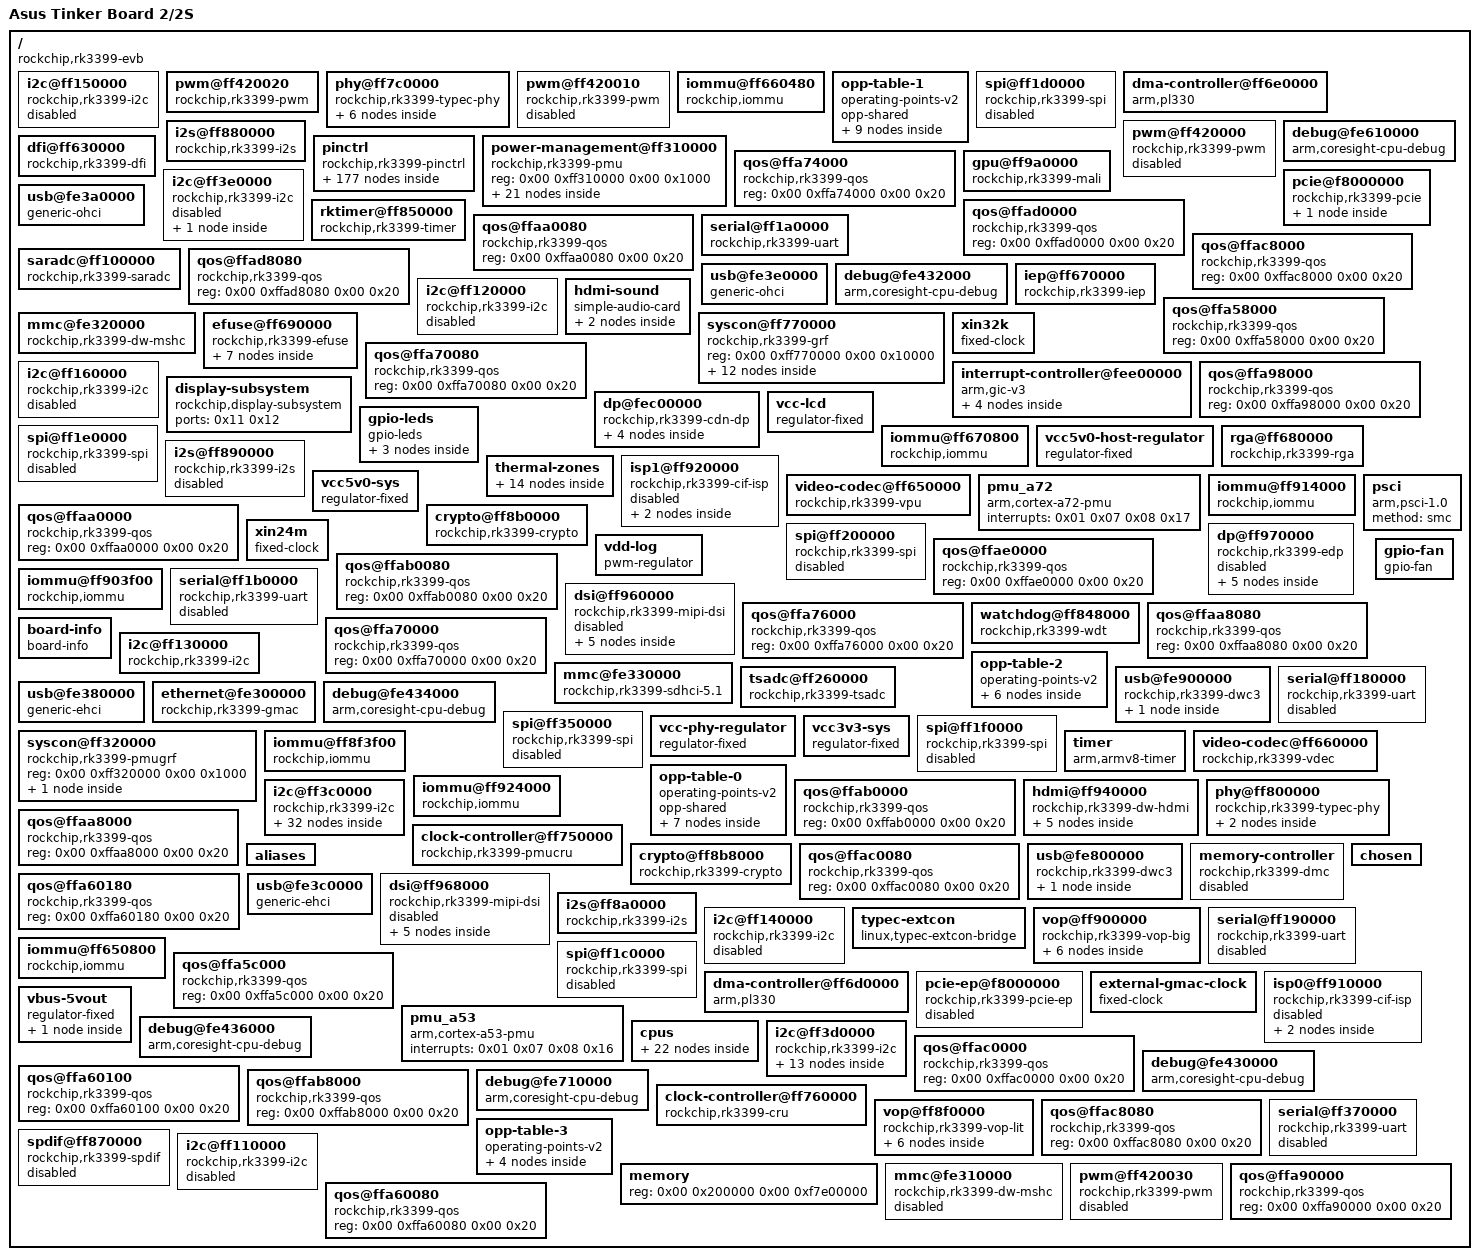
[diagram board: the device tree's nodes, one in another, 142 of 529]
/dts-v1/;

/ {
	#address-cells = <0x02>;
	model = "Asus Tinker Board 2/2S";
	serial-number = "3ae0242313a34723";
	#size-cells = <0x02>;
	interrupt-parent = <0x01>;
	compatible = "rockchip,rk3399-evb", "rockchip,rk3399";

	i2c@ff150000 {
		pinctrl-names = "default";
		#address-cells = <0x01>;
		pinctrl-0 = <0x3a>;
		clock-names = "i2c", "pclk";
		assigned-clocks = <0x08 0x45>;
		assigned-clock-rates = <0xbebc200>;
		interrupts = <0x00 0x25 0x04 0x00>;
		clocks = <0x08 0x45 0x08 0x159>;
		#size-cells = <0x00>;
		compatible = "rockchip,rk3399-i2c";
		status = "disabled";
		reg = <0x00 0xff150000 0x00 0x1000>;
		phandle = <0xd8>;
	};

	pwm@ff420020 {
		pinctrl-names = "default";
		pinctrl-0 = <0x89>;
		clocks = <0x72 0x1e>;
		#pwm-cells = <0x03>;
		compatible = "rockchip,rk3399-pwm", "rockchip,rk3288-pwm";
		status = "okay";
		reg = <0x00 0xff420020 0x00 0x10>;
		phandle = <0xc1>;
	};

	phy@ff7c0000 {
		power-domains = <0x1e 0x08>;
		clock-names = "tcpdcore", "tcpdphy-ref";
		assigned-clocks = <0x08 0x7e>;
		assigned-clock-rates = <0x2faf080>;
		resets = <0x08 0x95 0x08 0x94 0x08 0x14c>;
		clocks = <0x08 0x7e 0x08 0x7d>;
		extcon = <0x30>;
		compatible = "rockchip,rk3399-typec-phy";
		status = "okay";
		rockchip,grf = <0x1f>;
		reg = <0x00 0xff7c0000 0x00 0x40000>;
		phandle = <0x110>;
		reset-names = "uphy", "uphy-pipe", "uphy-tcphy";

		dp-port {
			#phy-cells = <0x00>;
			phandle = <0x33>;

			port {

				endpoint {
					remote-endpoint = <0x92>;
					phandle = <0x84>;
				};
			};
		};

		usb3-port {
			#phy-cells = <0x00>;
			phandle = <0x2f>;

			port {

				endpoint {
					remote-endpoint = <0x93>;
					phandle = <0x83>;
				};
			};
		};
	};

	pwm@ff420010 {
		pinctrl-names = "default";
		pinctrl-0 = <0x88>;
		clocks = <0x72 0x1e>;
		#pwm-cells = <0x03>;
		compatible = "rockchip,rk3399-pwm", "rockchip,rk3288-pwm";
		status = "disabled";
		reg = <0x00 0xff420010 0x00 0x10>;
		phandle = <0x101>;
	};

	iommu@ff660480 {
		power-domains = <0x1e 0x20>;
		clock-names = "aclk", "iface";
		interrupts = <0x00 0x75 0x04 0x00>;
		clocks = <0x08 0xed 0x08 0x1ec>;
		#iommu-cells = <0x00>;
		compatible = "rockchip,iommu";
		reg = <0x00 0xff660480 0x00 0x40 0x00 0xff6604c0 0x00 0x40>;
		phandle = <0x8c>;
	};

	opp-table-1 {
		opp-shared;
		compatible = "operating-points-v2";
		phandle = <0x0f>;

		opp04 {
			opp-microvolt = <0xdbba0 0xdbba0 0x1312d0>;
			opp-hz = <0x00 0x47868c00>;
		};

		opp02 {
			opp-microvolt = <0xc96a8 0xc96a8 0x1312d0>;
			opp-hz = <0x00 0x30a32c00>;
		};

		opp00 {
			opp-microvolt = <0xc3500 0xc3500 0x1312d0>;
			opp-hz = <0x00 0x18519600>;
			clock-latency-ns = <0x9c40>;
		};

		opp07 {
			opp-microvolt = <0x118c30 0x118c30 0x1312d0>;
			opp-hz = <0x00 0x6b49d200>;
		};

		opp05 {
			opp-microvolt = <0xee098 0xee098 0x1312d0>;
			opp-hz = <0x00 0x54667200>;
		};

		opp03 {
			opp-microvolt = <0xcf850 0xcf850 0x1312d0>;
			opp-hz = <0x00 0x3c14dc00>;
		};

		opp01 {
			opp-microvolt = <0xc3500 0xc3500 0x1312d0>;
			opp-hz = <0x00 0x23c34600>;
		};

		opp08 {
			opp-microvolt = <0x1312d0 0x1312d0 0x1312d0>;
			opp-hz = <0x00 0x7829b800>;
		};

		opp06 {
			opp-microvolt = <0x100590 0x100590 0x1312d0>;
			opp-hz = <0x00 0x5fd82200>;
		};
	};

	spi@ff1d0000 {
		pinctrl-names = "default";
		#address-cells = <0x01>;
		pinctrl-0 = <0x45 0x46 0x47 0x48>;
		clock-names = "spiclk", "apb_pclk";
		interrupts = <0x00 0x35 0x04 0x00>;
		clocks = <0x08 0x48 0x08 0x15c>;
		#size-cells = <0x00>;
		dma-names = "tx", "rx";
		compatible = "rockchip,rk3399-spi", "rockchip,rk3066-spi";
		status = "disabled";
		reg = <0x00 0xff1d0000 0x00 0x1000>;
		phandle = <0xdf>;
		dmas = <0x40 0x0c 0x40 0x0d>;
	};

	dma-controller@ff6e0000 {
		clock-names = "apb_pclk";
		interrupts = <0x00 0x07 0x04 0x00 0x00 0x08 0x04 0x00>;
		clocks = <0x08 0xd4>;
		arm,pl330-periph-burst;
		compatible = "arm,pl330", "arm,primecell";
		reg = <0x00 0xff6e0000 0x00 0x4000>;
		phandle = <0x40>;
		#dma-cells = <0x01>;
	};

	i2s@ff880000 {
		power-domains = <0x1e 0x1c>;
		rockchip,capture-channels = <0x08>;
		pinctrl-names = "bclk_on", "bclk_off";
		pinctrl-0 = <0x95>;
		clock-names = "i2s_clk", "i2s_hclk";
		interrupts = <0x00 0x27 0x04 0x00>;
		clocks = <0x08 0x56 0x08 0x1d4>;
		dma-names = "tx", "rx";
		#sound-dai-cells = <0x00>;
		rockchip,playback-channels = <0x08>;
		compatible = "rockchip,rk3399-i2s", "rockchip,rk3066-i2s";
		pinctrl-1 = <0x96>;
		status = "okay";
		rockchip,grf = <0x1f>;
		reg = <0x00 0xff880000 0x00 0x1000>;
		phandle = <0x115>;
		dmas = <0x51 0x00 0x51 0x01>;
	};

	pwm@ff420000 {
		pinctrl-names = "default";
		pinctrl-0 = <0x87>;
		clocks = <0x72 0x1e>;
		#pwm-cells = <0x03>;
		compatible = "rockchip,rk3399-pwm", "rockchip,rk3288-pwm";
		status = "disabled";
		reg = <0x00 0xff420000 0x00 0x10>;
		phandle = <0x100>;
	};

	debug@fe610000 {
		clock-names = "apb_pclk";
		clocks = <0x08 0x14c>;
		cpu = <0x06>;
		compatible = "arm,coresight-cpu-debug", "arm,primecell";
		reg = <0x00 0xfe610000 0x00 0x1000>;
	};

	pinctrl {
		#address-cells = <0x02>;
		#size-cells = <0x02>;
		compatible = "rockchip,rk3399-pinctrl";
		rockchip,pmu = <0x13>;
		ranges;
		rockchip,grf = <0x1f>;
		phandle = <0x126>;

		i2c3 {

			i2c3-xfer {
				rockchip,pins = <0x04 0x11 0x01 0xb6 0x04 0x10 0x01 0xb6>;
				phandle = <0x38>;
			};
		};

		clock {

			clk-32k {
				rockchip,pins = <0x00 0x00 0x02 0xb6>;
				phandle = <0x136>;
			};
		};

		spi2 {

			spi2-clk {
				rockchip,pins = <0x02 0x0b 0x01 0xb9>;
				phandle = <0x49>;
			};

			spi2-cs0 {
				rockchip,pins = <0x02 0x0c 0x01 0xb9>;
				phandle = <0x4c>;
			};

			spi2-tx {
				rockchip,pins = <0x02 0x0a 0x01 0xb9>;
				phandle = <0x4a>;
			};

			spi2-rx {
				rockchip,pins = <0x02 0x09 0x01 0xb9>;
				phandle = <0x4b>;
			};
		};

		pcfg-pull-none-12ma {
			drive-strength = <0x0c>;
			bias-disable;
			phandle = <0xb8>;
		};

		pcfg-pull-up-20ma {
			drive-strength = <0x14>;
			phandle = <0x12b>;
			bias-pull-up;
		};

		gpio@ff720000 {
			gpio-controller;
			interrupts = <0x00 0x0e 0x04 0x00>;
			clocks = <0x72 0x17>;
			compatible = "rockchip,gpio-bank";
			#interrupt-cells = <0x02>;
			reg = <0x00 0xff720000 0x00 0x100>;
			phandle = <0x1b>;
			#gpio-cells = <0x02>;
			interrupt-controller;
		};

		pcfg-input-pull-up {
			phandle = <0x134>;
			bias-pull-up;
			input-enable;
		};

		i2s1 {

			i2s1-2ch-bus-bclk-off {
				rockchip,pins = <0x04 0x03 0x00 0xb6 0x04 0x04 0x01 0xb6 0x04 0x05 0x01 0xb6 0x04 0x06 0x01 0xb6 0x04 0x07 0x01 0xb6>;
				phandle = <0x13c>;
			};

			i2s1-2ch-bus {
				rockchip,pins = <0x04 0x03 0x01 0xb6 0x04 0x04 0x01 0xb6 0x04 0x05 0x01 0xb6 0x04 0x06 0x01 0xb6 0x04 0x07 0x01 0xb6>;
				phandle = <0x97>;
			};
		};

		i2c1 {

			i2c1-xfer {
				rockchip,pins = <0x04 0x02 0x01 0xb6 0x04 0x01 0x01 0xb6>;
				phandle = <0x36>;
			};
		};

		gmac {

			rmii-pins {
				rockchip,pins = <0x03 0x0d 0x01 0xb6 0x03 0x0c 0x01 0xb7 0x03 0x0b 0x01 0xb6 0x03 0x0a 0x01 0xb6 0x03 0x09 0x01 0xb6 0x03 0x08 0x01 0xb6 0x03 0x07 0x01 0xb6 0x03 0x06 0x01 0xb6 0x03 0x05 0x01 0xb7 0x03 0x04 0x01 0xb7>;
				phandle = <0x139>;
			};

			rgmii-pins {
				rockchip,pins = <0x03 0x11 0x01 0xb7 0x03 0x0e 0x01 0xb6 0x03 0x0d 0x01 0xb6 0x03 0x0c 0x01 0xb7 0x03 0x0b 0x01 0xb6 0x03 0x09 0x01 0xb6 0x03 0x08 0x01 0xb6 0x03 0x07 0x01 0xb6 0x03 0x06 0x01 0xb6 0x03 0x05 0x01 0xb7 0x03 0x04 0x01 0xb7 0x03 0x03 0x01 0xb6 0x03 0x02 0x01 0xb6 0x03 0x01 0x01 0xb7 0x03 0x00 0x01 0xb7>;
				phandle = <0x21>;
			};
		};

		usb-typec {

			vcc5v0-typec0-en-pin {
				rockchip,pins = <0x01 0x03 0x00 0xb9>;
				phandle = <0xc0>;
			};
		};

		spi0 {

			spi0-tx {
				rockchip,pins = <0x03 0x05 0x02 0xb9>;
				phandle = <0x42>;
			};

			spi0-rx {
				rockchip,pins = <0x03 0x04 0x02 0xb9>;
				phandle = <0x43>;
			};

			spi0-cs1 {
				rockchip,pins = <0x03 0x08 0x02 0xb9>;
				phandle = <0x14c>;
			};

			spi0-clk {
				rockchip,pins = <0x03 0x06 0x02 0xb9>;
				phandle = <0x41>;
			};

			spi0-cs0 {
				rockchip,pins = <0x03 0x07 0x02 0xb9>;
				phandle = <0x44>;
			};
		};

		pcfg-pull-down-4ma {
			drive-strength = <0x04>;
			bias-pull-down;
			phandle = <0x12c>;
		};

		pcfg-pull-down {
			bias-pull-down;
			phandle = <0xbb>;
		};

		uart4 {

			uart4-xfer {
				rockchip,pins = <0x01 0x07 0x01 0xb9 0x01 0x08 0x01 0xb6>;
				phandle = <0x77>;
			};
		};

		pcfg-pull-none-18ma {
			drive-strength = <0x12>;
			bias-disable;
			phandle = <0x127>;
		};

		i2c8 {

			i2c8-xfer {
				rockchip,pins = <0x01 0x15 0x01 0xb6 0x01 0x14 0x01 0xb6>;
				phandle = <0x86>;
			};
		};

		pcfg-input-pull-down {
			bias-pull-down;
			phandle = <0x135>;
			input-enable;
		};

		pcfg-pull-none-20ma {
			drive-strength = <0x14>;
			bias-disable;
			phandle = <0x128>;
		};

		gpio@ff730000 {
			gpio-controller;
			interrupts = <0x00 0x0f 0x04 0x00>;
			clocks = <0x72 0x18>;
			compatible = "rockchip,gpio-bank";
			#interrupt-cells = <0x02>;
			reg = <0x00 0xff730000 0x00 0x100>;
			phandle = <0x79>;
			#gpio-cells = <0x02>;
			interrupt-controller;
		};

		i2c6 {

			i2c6-xfer {
				rockchip,pins = <0x02 0x0a 0x02 0xb6 0x02 0x09 0x02 0xb6>;
				phandle = <0x3a>;
			};
		};

		uarthdcp {

			uarthdcp-xfer {
				rockchip,pins = <0x04 0x15 0x02 0xb9 0x04 0x16 0x02 0xb6>;
				phandle = <0x156>;
			};
		};

		pwm1 {

			pwm1-pin {
				rockchip,pins = <0x04 0x16 0x01 0xb6>;
				phandle = <0x88>;
			};

			pwm1-pin-pull-down {
				rockchip,pins = <0x04 0x16 0x01 0xbb>;
				phandle = <0x15a>;
			};
		};

		uart2b {

			uart2b-xfer {
				rockchip,pins = <0x04 0x10 0x02 0xb9 0x04 0x11 0x02 0xb6>;
				phandle = <0x153>;
			};
		};

		edp {

			edp-hpd {
				rockchip,pins = <0x04 0x17 0x02 0xb6>;
				phandle = <0xb1>;
			};
		};

		spi5 {

			spi5-cs0 {
				rockchip,pins = <0x02 0x17 0x02 0xb9>;
				phandle = <0x55>;
			};

			spi5-tx {
				rockchip,pins = <0x02 0x15 0x02 0xb9>;
				phandle = <0x53>;
			};

			spi5-rx {
				rockchip,pins = <0x02 0x14 0x02 0xb9>;
				phandle = <0x54>;
			};

			spi5-clk {
				rockchip,pins = <0x02 0x16 0x02 0xb9>;
				phandle = <0x52>;
			};
		};

		tsadc {

			otp-pin {
				rockchip,pins = <0x01 0x06 0x00 0xb6>;
				phandle = <0x5b>;
			};

			otp-out {
				rockchip,pins = <0x01 0x06 0x01 0xb6>;
				phandle = <0x5c>;
			};
		};

		uart0 {

			uart0-cts {
				rockchip,pins = <0x02 0x12 0x01 0xb6>;
				phandle = <0x150>;
			};

			uart0-rts {
				rockchip,pins = <0x02 0x13 0x01 0xb6>;
				phandle = <0x151>;
			};

			uart0-xfer {
				rockchip,pins = <0x02 0x10 0x01 0xb9 0x02 0x11 0x01 0xb6>;
				phandle = <0x3c>;
			};
		};

		i2c4 {

			i2c4-xfer {
				rockchip,pins = <0x01 0x0c 0x01 0xb6 0x01 0x0b 0x01 0xb6>;
				phandle = <0x7f>;
			};
		};

		pcfg-pull-down-12ma {
			drive-strength = <0x0c>;
			bias-pull-down;
			phandle = <0x12e>;
		};

		spdif {

			spdif-bus-1 {
				rockchip,pins = <0x03 0x10 0x03 0xb6>;
				phandle = <0x14b>;
			};

			spdif-bus {
				rockchip,pins = <0x04 0x15 0x01 0xb6>;
				phandle = <0x94>;
			};
		};

		pcfg-output-high {
			output-high;
			phandle = <0x131>;
		};

		pcie {

			pci-clkreqn-cpm {
				rockchip,pins = <0x02 0x1a 0x00 0xb6>;
				phandle = <0x1c>;
			};

			pci-clkreqnb-cpm {
				rockchip,pins = <0x04 0x18 0x00 0xb6>;
				phandle = <0x1d>;
			};
		};

		pcfg-pull-up {
			phandle = <0xb9>;
			bias-pull-up;
		};

		spi3 {

			spi3-tx {
				rockchip,pins = <0x01 0x10 0x01 0xb9>;
				phandle = <0x74>;
			};

			spi3-rx {
				rockchip,pins = <0x01 0x0f 0x01 0xb9>;
				phandle = <0x75>;
			};

			spi3-clk {
				rockchip,pins = <0x01 0x11 0x01 0xb9>;
				phandle = <0x73>;
			};

			spi3-cs0 {
				rockchip,pins = <0x01 0x12 0x01 0xb9>;
				phandle = <0x76>;
			};
		};

		pwm3a {

			pwm3a-pin {
				rockchip,pins = <0x00 0x06 0x01 0xb6>;
				phandle = <0x8a>;
			};
		};

		sdio0 {

			sdio0-clk {
				rockchip,pins = <0x02 0x19 0x01 0xb6>;
				phandle = <0x140>;
			};

			sdio0-wp {
				rockchip,pins = <0x00 0x03 0x01 0xb9>;
				phandle = <0x144>;
			};

			sdio0-bus4 {
				rockchip,pins = <0x02 0x14 0x01 0xb9 0x02 0x15 0x01 0xb9 0x02 0x16 0x01 0xb9 0x02 0x17 0x01 0xb9>;
				phandle = <0x13e>;
			};

			sdmmc-pwr {
				rockchip,pins = <0x00 0x01 0x01 0xb9>;
				phandle = <0x146>;
			};

			sdio0-bkpwr {
				rockchip,pins = <0x02 0x1c 0x01 0xb9>;
				phandle = <0x143>;
			};

			sdio0-cd {
				rockchip,pins = <0x02 0x1a 0x01 0xb9>;
				phandle = <0x141>;
			};

			sdio0-pwr {
				rockchip,pins = <0x02 0x1b 0x01 0xb9>;
				phandle = <0x142>;
			};

			sdio0-int {
				rockchip,pins = <0x00 0x04 0x01 0xb9>;
				phandle = <0x145>;
			};

			sdio0-bus1 {
				rockchip,pins = <0x02 0x14 0x01 0xb9>;
				phandle = <0x13d>;
			};

			sdio0-cmd {
				rockchip,pins = <0x02 0x18 0x01 0xb9>;
				phandle = <0x13f>;
			};
		};

		pcfg-pull-up-2ma {
			drive-strength = <0x02>;
			phandle = <0x129>;
			bias-pull-up;
		};

		i2c2 {

			i2c2-xfer {
				rockchip,pins = <0x02 0x01 0x02 0xb8 0x02 0x00 0x02 0xb8>;
				phandle = <0x37>;
			};
		};

		pmic {

			vsel2-gpio {
				rockchip,pins = <0x01 0x0e 0x00 0xbb>;
				phandle = <0x85>;
			};

			vsel1-gpio {
				rockchip,pins = <0x01 0x11 0x00 0xbb>;
				phandle = <0x7e>;
			};

			pmic-int-l {
				rockchip,pins = <0x01 0x12 0x00 0xb9 0x00 0x09 0x00 0xb6>;
				phandle = <0x7a>;
			};
		};

		pcfg-input-enable {
			phandle = <0x133>;
			input-enable;
		};

		pcfg-pull-none {
			bias-disable;
			phandle = <0xb6>;
		};

		spi1 {

			spi1-cs0 {
				rockchip,pins = <0x01 0x0a 0x02 0xb9>;
				phandle = <0x48>;
			};

			spi1-clk {
				rockchip,pins = <0x01 0x09 0x02 0xb9>;
				phandle = <0x45>;
			};

			spi1-tx {
				rockchip,pins = <0x01 0x08 0x02 0xb9>;
				phandle = <0x46>;
			};

			spi1-rx {
				rockchip,pins = <0x01 0x07 0x02 0xb9>;
				phandle = <0x47>;
			};
		};

		gpio@ff780000 {
			gpio-controller;
			interrupts = <0x00 0x10 0x04 0x00>;
			clocks = <0x08 0x150>;
			compatible = "rockchip,gpio-bank";
			#interrupt-cells = <0x02>;
			reg = <0x00 0xff780000 0x00 0x100>;
			phandle = <0xbd>;
			#gpio-cells = <0x02>;
			interrupt-controller;
		};

		pcfg-pull-down-18ma {
			drive-strength = <0x12>;
			bias-pull-down;
			phandle = <0x12f>;
		};

		sdmmc {

			sdmmc-wp {
				rockchip,pins = <0x00 0x08 0x01 0xba>;
				phandle = <0x148>;
			};

			sdmmc-bus1 {
				rockchip,pins = <0x04 0x08 0x01 0xba>;
				phandle = <0x147>;
			};

			sdmmc-cd {
				rockchip,pins = <0x00 0x07 0x01 0xb9>;
				phandle = <0x27>;
			};

			sdmmc-bus4 {
				rockchip,pins = <0x04 0x08 0x01 0xba 0x04 0x09 0x01 0xba 0x04 0x0a 0x01 0xba 0x04 0x0b 0x01 0xba>;
				phandle = <0x28>;
			};

			sdmmc-cmd {
				rockchip,pins = <0x04 0x0d 0x01 0xba>;
				phandle = <0x26>;
			};

			sdmmc-clk {
				rockchip,pins = <0x04 0x0c 0x01 0xb8>;
				phandle = <0x25>;
			};
		};

		i2s0 {

			i2s0-8ch-bus {
				rockchip,pins = <0x03 0x18 0x01 0xb6 0x03 0x19 0x01 0xb6 0x03 0x1a 0x01 0xb6 0x03 0x1b 0x01 0xb6 0x03 0x1c 0x01 0xb6 0x03 0x1d 0x01 0xb6 0x03 0x1e 0x01 0xb6 0x03 0x1f 0x01 0xb6 0x04 0x00 0x01 0xb6>;
				phandle = <0x95>;
			};

			i2s0-8ch-bus-bclk-off {
				rockchip,pins = <0x03 0x18 0x00 0xb6 0x03 0x19 0x01 0xb6 0x03 0x1a 0x01 0xb6 0x03 0x1b 0x01 0xb6 0x03 0x1c 0x01 0xb6 0x03 0x1d 0x01 0xb6 0x03 0x1e 0x01 0xb6 0x03 0x1f 0x01 0xb6 0x04 0x00 0x01 0xb6>;
				phandle = <0x96>;
			};

			i2s0-2ch-bus-bclk-off {
				rockchip,pins = <0x03 0x18 0x00 0xb6 0x03 0x19 0x01 0xb6 0x03 0x1a 0x01 0xb6 0x03 0x1b 0x01 0xb6 0x03 0x1f 0x01 0xb6 0x04 0x00 0x01 0xb6>;
				phandle = <0x13b>;
			};

			i2s0-2ch-bus {
				rockchip,pins = <0x03 0x18 0x01 0xb6 0x03 0x19 0x01 0xb6 0x03 0x1a 0x01 0xb6 0x03 0x1b 0x01 0xb6 0x03 0x1f 0x01 0xb6 0x04 0x00 0x01 0xb6>;
				phandle = <0x13a>;
			};
		};

		i2c0 {

			i2c0-xfer {
				rockchip,pins = <0x01 0x0f 0x02 0xb6 0x01 0x10 0x02 0xb6>;
				phandle = <0x78>;
			};
		};

		suspend {

			ap-pwroff {
				rockchip,pins = <0x01 0x05 0x01 0xb6>;
				phandle = <0x149>;
			};

			ddrio-pwroff {
				rockchip,pins = <0x00 0x01 0x01 0xb6>;
				phandle = <0x14a>;
			};
		};

		usb2 {

			vcc5v0-host-en {
				rockchip,pins = <0x04 0x19 0x00 0xb6>;
				phandle = <0xbf>;
			};
		};

		testclk {

			test-clkout2 {
				rockchip,pins = <0x00 0x08 0x03 0xb6>;
				phandle = <0x14f>;
			};

			test-clkout0 {
				rockchip,pins = <0x00 0x00 0x01 0xb6>;
				phandle = <0x14d>;
			};

			test-clkout1 {
				rockchip,pins = <0x02 0x19 0x02 0xb6>;
				phandle = <0x14e>;
			};
		};

		pcfg-pull-up-8ma {
			drive-strength = <0x08>;
			phandle = <0xba>;
			bias-pull-up;
		};

		pcfg-pull-down-20ma {
			drive-strength = <0x14>;
			bias-pull-down;
			phandle = <0x130>;
		};

		pcfg-pull-none-13ma {
			drive-strength = <0x0d>;
			bias-disable;
			phandle = <0xb7>;
		};

		fusb30x {

			fusb0-int {
				rockchip,pins = <0x01 0x02 0x00 0xb9>;
				phandle = <0x80>;
			};
		};

		uart3 {

			uart3-cts {
				rockchip,pins = <0x03 0x10 0x02 0xb6>;
				phandle = <0x154>;
			};

			uart3-rts {
				rockchip,pins = <0x03 0x11 0x02 0xb6>;
				phandle = <0x155>;
			};

			uart3-xfer {
				rockchip,pins = <0x03 0x0e 0x02 0xb9 0x03 0x0f 0x02 0xb6>;
				phandle = <0x3f>;
			};
		};

		pcfg-output-low {
			phandle = <0x132>;
			output-low;
		};

		i2c7 {

			i2c7-xfer {
				rockchip,pins = <0x02 0x08 0x02 0xb6 0x02 0x07 0x02 0xb6>;
				phandle = <0x3b>;
			};
		};

		pwm2 {

			pwm2-pin {
				rockchip,pins = <0x01 0x13 0x01 0xb6>;
				phandle = <0x15b>;
			};

			pwm2-pin-pull-down {
				rockchip,pins = <0x01 0x13 0x01 0xbb>;
				phandle = <0x89>;
			};
		};

		uart2c {

			uart2c-xfer {
				rockchip,pins = <0x04 0x13 0x01 0xb9 0x04 0x14 0x01 0xb6>;
				phandle = <0x3e>;
			};
		};

		fan {

			gpio-fan-pin {
				rockchip,pins = <0x04 0x1a 0x00 0xb6>;
				phandle = <0xbe>;
			};
		};

		uart1 {

			uart1-xfer {
				rockchip,pins = <0x03 0x0c 0x02 0xb9 0x03 0x0d 0x02 0xb6>;
				phandle = <0x3d>;
			};
		};

		hdmi {

			hdmi-i2c-xfer {
				rockchip,pins = <0x04 0x11 0x03 0xb6 0x04 0x10 0x03 0xb6>;
				phandle = <0x15d>;
			};

			hdmi-cec {
				rockchip,pins = <0x04 0x17 0x01 0xb6>;
				phandle = <0x15e>;
			};
		};

		gpio@ff790000 {
			gpio-controller;
			interrupts = <0x00 0x12 0x04 0x00>;
			clocks = <0x08 0x152>;
			compatible = "rockchip,gpio-bank";
			#interrupt-cells = <0x02>;
			reg = <0x00 0xff790000 0x00 0x100>;
			phandle = <0xbc>;
			#gpio-cells = <0x02>;
			interrupt-controller;
		};

		i2c5 {

			i2c5-xfer {
				rockchip,pins = <0x03 0x0b 0x02 0xb6 0x03 0x0a 0x02 0xb6>;
				phandle = <0x39>;
			};
		};

		gpio@ff788000 {
			gpio-controller;
			interrupts = <0x00 0x11 0x04 0x00>;
			clocks = <0x08 0x151>;
			compatible = "rockchip,gpio-bank";
			#interrupt-cells = <0x02>;
			reg = <0x00 0xff788000 0x00 0x100>;
			phandle = <0x22>;
			#gpio-cells = <0x02>;
			interrupt-controller;
		};

		pwm0 {

			pwm0-pin-pull-down {
				rockchip,pins = <0x04 0x12 0x01 0xbb>;
				phandle = <0x157>;
			};

			vop1-pwm-pin {
				rockchip,pins = <0x04 0x12 0x03 0xb6>;
				phandle = <0x159>;
			};

			vop0-pwm-pin {
				rockchip,pins = <0x04 0x12 0x02 0xb6>;
				phandle = <0x158>;
			};

			pwm0-pin {
				rockchip,pins = <0x04 0x12 0x01 0xb6>;
				phandle = <0x87>;
			};
		};

		cif {

			cif-clkin {
				rockchip,pins = <0x02 0x0a 0x03 0xb6>;
				phandle = <0x137>;
			};

			cif-clkouta {
				rockchip,pins = <0x02 0x0b 0x03 0xb6>;
				phandle = <0x138>;
			};
		};

		uart2a {

			uart2a-xfer {
				rockchip,pins = <0x04 0x08 0x02 0xb9 0x04 0x09 0x02 0xb6>;
				phandle = <0x152>;
			};
		};

		spi4 {

			spi4-clk {
				rockchip,pins = <0x03 0x02 0x02 0xb9>;
				phandle = <0x4d>;
			};

			spi4-tx {
				rockchip,pins = <0x03 0x01 0x02 0xb9>;
				phandle = <0x4e>;
			};

			spi4-rx {
				rockchip,pins = <0x03 0x00 0x02 0xb9>;
				phandle = <0x4f>;
			};

			spi4-cs0 {
				rockchip,pins = <0x03 0x03 0x02 0xb9>;
				phandle = <0x50>;
			};
		};

		pcfg-pull-down-8ma {
			drive-strength = <0x08>;
			bias-pull-down;
			phandle = <0x12d>;
		};

		pwm3b {

			pwm3b-pin {
				rockchip,pins = <0x01 0x0e 0x01 0xb6>;
				phandle = <0x15c>;
			};
		};

		pcfg-pull-up-18ma {
			drive-strength = <0x12>;
			phandle = <0x12a>;
			bias-pull-up;
		};
	};

	power-management@ff310000 {
		compatible = "rockchip,rk3399-pmu", "syscon", "simple-mfd";
		reg = <0x00 0xff310000 0x00 0x1000>;
		phandle = <0xec>;

		power-controller {
			#address-cells = <0x01>;
			#size-cells = <0x00>;
			#power-domain-cells = <0x01>;
			compatible = "rockchip,rk3399-power-controller";
			phandle = <0x1e>;

			power-domain@9 {
				clocks = <0x08 0x80 0x08 0x7f>;
				#power-domain-cells = <0x00>;
				reg = <0x09>;
			};

			power-domain@27 {
				clocks = <0x08 0x1ce 0x08 0x4c>;
				#power-domain-cells = <0x00>;
				reg = <0x1b>;
				pm_qos = <0x66>;
			};

			power-domain@35 {
				clocks = <0x08 0xd0>;
				#power-domain-cells = <0x00>;
				reg = <0x23>;
				pm_qos = <0x63>;
			};

			power-domain@25 {
				clocks = <0x08 0x16c>;
				#power-domain-cells = <0x00>;
				reg = <0x19>;
			};

			power-domain@15 {
				#address-cells = <0x01>;
				#size-cells = <0x00>;
				#power-domain-cells = <0x01>;
				reg = <0x0f>;

				power-domain@19 {
					clocks = <0x08 0xe5 0x08 0x1df>;
					#power-domain-cells = <0x00>;
					reg = <0x13>;
					pm_qos = <0x6b 0x6c>;
				};

				power-domain@21 {
					clocks = <0x08 0xde 0x08 0x1e7 0x08 0x172>;
					#power-domain-cells = <0x00>;
					reg = <0x15>;
					pm_qos = <0x6a>;
				};

				power-domain@16 {
					#address-cells = <0x01>;
					#size-cells = <0x00>;
					#power-domain-cells = <0x01>;
					reg = <0x10>;

					power-domain@17 {
						clocks = <0x08 0xd9 0x08 0x1d9>;
						#power-domain-cells = <0x00>;
						reg = <0x11>;
						pm_qos = <0x6f 0x70>;
					};

					power-domain@18 {
						clocks = <0x08 0xdb 0x08 0x1db>;
						#power-domain-cells = <0x00>;
						reg = <0x12>;
						pm_qos = <0x71>;
					};
				};

				power-domain@20 {
					clocks = <0x08 0xe6 0x08 0x1e0>;
					#power-domain-cells = <0x00>;
					reg = <0x14>;
					pm_qos = <0x6d 0x6e>;
				};
			};

			power-domain@33 {
				clocks = <0x08 0xdc 0x08 0x1e5>;
				#power-domain-cells = <0x00>;
				reg = <0x21>;
				pm_qos = <0x5e 0x5f>;
			};

			power-domain@23 {
				clocks = <0x08 0xf0>;
				#power-domain-cells = <0x00>;
				reg = <0x17>;
				pm_qos = <0x64>;
			};

			power-domain@31 {
				clocks = <0x08 0xeb 0x08 0x1ea>;
				#power-domain-cells = <0x00>;
				reg = <0x1f>;
				pm_qos = <0x60>;
			};

			power-domain@28 {
				clocks = <0x08 0x1ee>;
				#power-domain-cells = <0x00>;
				reg = <0x1c>;
				pm_qos = <0x67>;
			};

			power-domain@8 {
				clocks = <0x08 0x7e 0x08 0x7d>;
				#power-domain-cells = <0x00>;
				reg = <0x08>;
			};

			power-domain@34 {
				clocks = <0x08 0xe1 0x08 0x1dd>;
				#power-domain-cells = <0x00>;
				reg = <0x22>;
				pm_qos = <0x5d>;
			};

			power-domain@24 {
				clocks = <0x08 0xf4>;
				#power-domain-cells = <0x00>;
				reg = <0x18>;
				pm_qos = <0x68 0x69>;
			};

			power-domain@32 {
				clocks = <0x08 0xed 0x08 0x1ec 0x08 0x9f 0x08 0x9e>;
				#power-domain-cells = <0x00>;
				reg = <0x20>;
				pm_qos = <0x61 0x62>;
			};

			power-domain@22 {
				clocks = <0x08 0xd5 0x08 0x166>;
				#power-domain-cells = <0x00>;
				reg = <0x16>;
				pm_qos = <0x65>;
			};
		};
	};

	qos@ffa74000 {
		compatible = "rockchip,rk3399-qos", "syscon";
		reg = <0x00 0xffa74000 0x00 0x20>;
		phandle = <0x66>;
	};

	gpu@ff9a0000 {
		power-domains = <0x1e 0x23>;
		mali-supply = <0xb5>;
		interrupts = <0x00 0x14 0x04 0x00 0x00 0x15 0x04 0x00 0x00 0x13 0x04 0x00>;
		clocks = <0x08 0xd0>;
		compatible = "rockchip,rk3399-mali", "arm,mali-t860";
		dynamic-power-coefficient = <0xa50>;
		status = "okay";
		interrupt-names = "job", "mmu", "gpu";
		reg = <0x00 0xff9a0000 0x00 0x10000>;
		phandle = <0x5a>;
		operating-points-v2 = <0xb4>;
		#cooling-cells = <0x02>;
	};

	dfi@ff630000 {
		clock-names = "pclk_ddr_mon";
		interrupts = <0x00 0x83 0x04 0x00>;
		clocks = <0x08 0x179>;
		compatible = "rockchip,rk3399-dfi";
		rockchip,pmu = <0x13>;
		reg = <0x00 0xff630000 0x00 0x4000>;
		phandle = <0x14>;
	};

	i2c@ff3e0000 {
		pinctrl-names = "default";
		#address-cells = <0x01>;
		pinctrl-0 = <0x86>;
		clock-names = "i2c", "pclk";
		assigned-clocks = <0x72 0x0b>;
		assigned-clock-rates = <0xbebc200>;
		interrupts = <0x00 0x3a 0x04 0x00>;
		clocks = <0x72 0x0b 0x72 0x1d>;
		#size-cells = <0x00>;
		compatible = "rockchip,rk3399-i2c";
		status = "disabled";
		reg = <0x00 0xff3e0000 0x00 0x1000>;
		phandle = <0xfe>;

		m24c08@50 {
			compatible = "atmel,24c08";
			reg = <0x50>;
			phandle = <0xff>;
		};
	};

	pcie@f8000000 {
		pinctrl-names = "default";
		#address-cells = <0x03>;
		phy-names = "pcie-phy-0", "pcie-phy-1", "pcie-phy-2", "pcie-phy-3";
		bus-range = <0x00 0x1f>;
		pinctrl-0 = <0x1c>;
		clock-names = "aclk", "aclk-perf", "hclk", "pm";
		reg-names = "axi-base", "apb-base";
		ep-gpios = <0x1b 0x0c 0x00>;
		resets = <0x08 0x82 0x08 0x83 0x08 0x84 0x08 0x85 0x08 0x86 0x08 0x81 0x08 0x80>;
		interrupts = <0x00 0x31 0x04 0x00 0x00 0x32 0x04 0x00 0x00 0x33 0x04 0x00>;
		clocks = <0x08 0xc5 0x08 0xc4 0x08 0x147 0x08 0xa0>;
		interrupt-map = <0x00 0x00 0x00 0x01 0x18 0x00 0x00 0x00 0x00 0x02 0x18 0x01 0x00 0x00 0x00 0x03 0x18 0x02 0x00 0x00 0x00 0x04 0x18 0x03>;
		#size-cells = <0x02>;
		aspm-no-l0s;
		max-link-speed = <0x01>;
		device_type = "pci";
		interrupt-map-mask = <0x00 0x00 0x00 0x07>;
		num-lanes = <0x04>;
		compatible = "rockchip,rk3399-pcie";
		ranges = <0x82000000 0x00 0xfa000000 0x00 0xfa000000 0x00 0x1e00000 0x81000000 0x00 0xfbe00000 0x00 0xfbe00000 0x00 0x100000>;
		msi-map = <0x00 0x19 0x00 0x1000>;
		#interrupt-cells = <0x01>;
		status = "okay";
		interrupt-names = "sys", "legacy", "client";
		phys = <0x1a 0x00 0x1a 0x01 0x1a 0x02 0x1a 0x03>;
		reg = <0x00 0xf8000000 0x00 0x2000000 0x00 0xfd000000 0x00 0x1000000>;
		phandle = <0xc3>;
		reset-names = "core", "mgmt", "mgmt-sticky", "pipe", "pm", "pclk", "aclk";

		interrupt-controller {
			#address-cells = <0x00>;
			#interrupt-cells = <0x01>;
			phandle = <0x18>;
			interrupt-controller;
		};
	};

	qos@ffad0000 {
		compatible = "rockchip,rk3399-qos", "syscon";
		reg = <0x00 0xffad0000 0x00 0x20>;
		phandle = <0x71>;
	};

	rktimer@ff850000 {
		clock-names = "pclk", "timer";
		interrupts = <0x00 0x51 0x04 0x00>;
		clocks = <0x08 0x168 0x08 0x5a>;
		compatible = "rockchip,rk3399-timer";
		reg = <0x00 0xff850000 0x00 0x1000>;
		phandle = <0x113>;
	};

	qos@ffaa0080 {
		compatible = "rockchip,rk3399-qos", "syscon";
		reg = <0x00 0xffaa0080 0x00 0x20>;
		phandle = <0x6c>;
	};

	serial@ff1a0000 {
		reg-io-width = <0x04>;
		pinctrl-names = "default";
		pinctrl-0 = <0x3e>;
		clock-names = "baudclk", "apb_pclk";
		interrupts = <0x00 0x64 0x04 0x00>;
		clocks = <0x08 0x53 0x08 0x162>;
		compatible = "rockchip,rk3399-uart", "snps,dw-apb-uart";
		status = "okay";
		reg = <0x00 0xff1a0000 0x00 0x100>;
		phandle = <0xdc>;
		reg-shift = <0x02>;
	};

	qos@ffac8000 {
		compatible = "rockchip,rk3399-qos", "syscon";
		reg = <0x00 0xffac8000 0x00 0x20>;
		phandle = <0x6f>;
	};

	usb@fe3a0000 {
		phy-names = "usb";
		interrupts = <0x00 0x1c 0x04 0x00>;
		clocks = <0x08 0x1c8 0x08 0x1c9 0x2a>;
		compatible = "generic-ohci";
		status = "okay";
		phys = <0x2b>;
		reg = <0x00 0xfe3a0000 0x00 0x20000>;
		phandle = <0xc9>;
	};

	saradc@ff100000 {
		clock-names = "saradc", "apb_pclk";
		resets = <0x08 0xd4>;
		interrupts = <0x00 0x3e 0x04 0x00>;
		clocks = <0x08 0x50 0x08 0x165>;
		#io-channel-cells = <0x01>;
		compatible = "rockchip,rk3399-saradc";
		status = "okay";
		reg = <0x00 0xff100000 0x00 0x100>;
		phandle = <0xd2>;
		reset-names = "saradc-apb";
	};

	qos@ffad8080 {
		compatible = "rockchip,rk3399-qos", "syscon";
		reg = <0x00 0xffad8080 0x00 0x20>;
		phandle = <0xeb>;
	};

	usb@fe3e0000 {
		phy-names = "usb";
		interrupts = <0x00 0x20 0x04 0x00>;
		clocks = <0x08 0x1ca 0x08 0x1cb 0x2c>;
		compatible = "generic-ohci";
		status = "okay";
		phys = <0x2d>;
		reg = <0x00 0xfe3e0000 0x00 0x20000>;
		phandle = <0xcb>;
	};

	debug@fe432000 {
		clock-names = "apb_pclk";
		clocks = <0x08 0x14d>;
		cpu = <0x03>;
		compatible = "arm,coresight-cpu-debug", "arm,primecell";
		reg = <0x00 0xfe432000 0x00 0x1000>;
	};

	iep@ff670000 {
		power-domains = <0x1e 0x22>;
		iommus = <0x8d>;
		clock-names = "axi", "ahb";
		interrupts = <0x00 0x2a 0x04 0x00>;
		clocks = <0x08 0xe1 0x08 0x1dd>;
		compatible = "rockchip,rk3399-iep", "rockchip,rk3228-iep";
		interrupt-names = "iep";
		reg = <0x00 0xff670000 0x00 0x800>;
		phandle = <0x105>;
	};

	i2c@ff120000 {
		pinctrl-names = "default";
		#address-cells = <0x01>;
		pinctrl-0 = <0x37>;
		clock-names = "i2c", "pclk";
		assigned-clocks = <0x08 0x42>;
		assigned-clock-rates = <0xbebc200>;
		interrupts = <0x00 0x23 0x04 0x00>;
		clocks = <0x08 0x42 0x08 0x156>;
		#size-cells = <0x00>;
		compatible = "rockchip,rk3399-i2c";
		status = "disabled";
		reg = <0x00 0xff120000 0x00 0x1000>;
		phandle = <0xd6>;
	};

	qos@ffa58000 {
		compatible = "rockchip,rk3399-qos", "syscon";
		reg = <0x00 0xffa58000 0x00 0x20>;
		phandle = <0x64>;
	};

	mmc@fe320000 {
		power-domains = <0x1e 0x1b>;
		supports-sd;
		fifo-depth = <0x100>;
		clock-freq-min-max = <0x186a0 0x8f0d180>;
		pinctrl-names = "default";
		pinctrl-0 = <0x25 0x26 0x27 0x28>;
		clock-names = "biu", "ciu", "ciu-drive", "ciu-sample";
		cap-sd-highspeed;
		vqmmc-supply = <0x24>;
		assigned-clocks = <0x08 0x1cd>;
		bus-width = <0x04>;
		assigned-clock-rates = <0xbebc200>;
		resets = <0x08 0x7a>;
		interrupts = <0x00 0x41 0x04 0x00>;
		clocks = <0x08 0x1ce 0x08 0x4c 0x08 0x9a 0x08 0x9b>;
		num-slots = <0x01>;
		vmmc-supply = <0x23>;
		clock-frequency = <0x8f0d180>;
		compatible = "rockchip,rk3399-dw-mshc", "rockchip,rk3288-dw-mshc";
		status = "okay";
		disable-wp;
		reg = <0x00 0xfe320000 0x00 0x4000>;
		phandle = <0xc7>;
		max-frequency = <0x8f0d180>;
		cap-mmc-highspeed;
		reset-names = "reset";
	};

	hdmi-sound {
		simple-audio-card,name = "hdmi-sound";
		simple-audio-card,format = "i2s";
		compatible = "simple-audio-card";
		status = "okay";
		phandle = <0x11b>;
		simple-audio-card,mclk-fs = <0x100>;

		simple-audio-card,cpu {
			sound-dai = <0xa8>;
		};

		simple-audio-card,codec {
			sound-dai = <0xa9>;
		};
	};

	syscon@ff770000 {
		#address-cells = <0x01>;
		#size-cells = <0x01>;
		compatible = "rockchip,rk3399-grf", "syscon", "simple-mfd";
		reg = <0x00 0xff770000 0x00 0x10000>;
		phandle = <0x1f>;

		mipi-dphy-rx0 {
			power-domains = <0x1e 0x0f>;
			clock-names = "dphy-ref", "dphy-cfg", "grf";
			clocks = <0x08 0x77 0x08 0xa5 0x08 0x16f>;
			#phy-cells = <0x00>;
			compatible = "rockchip,rk3399-mipi-dphy-rx0";
			status = "disabled";
			phandle = <0xa5>;
		};

		pcie-phy {
			clock-names = "refclk";
			resets = <0x08 0x87>;
			clocks = <0x08 0x8a>;
			#phy-cells = <0x01>;
			compatible = "rockchip,rk3399-pcie-phy";
			status = "okay";
			phandle = <0x1a>;
			reset-names = "phy";
		};

		usb2phy@e460 {
			clock-output-names = "clk_usbphy1_480m";
			clock-names = "phyclk";
			clocks = <0x08 0x7c>;
			#clock-cells = <0x00>;
			compatible = "rockchip,rk3399-usb2phy";
			status = "okay";
			reg = <0xe460 0x10>;
			phandle = <0x2c>;

			host-port {
				phy-supply = <0x8f>;
				interrupts = <0x00 0x1f 0x04 0x00>;
				#phy-cells = <0x00>;
				status = "okay";
				interrupt-names = "linestate";
				phandle = <0x2d>;
			};

			otg-port {
				interrupts = <0x00 0x6c 0x04 0x00 0x00 0x6d 0x04 0x00 0x00 0x6f 0x04 0x00>;
				#phy-cells = <0x00>;
				status = "okay";
				interrupt-names = "otg-bvalid", "otg-id", "linestate";
				phandle = <0x31>;
			};
		};

		usb2phy@e450 {
			clock-output-names = "clk_usbphy0_480m";
			clock-names = "phyclk";
			clocks = <0x08 0x7b>;
			extcon = <0x30>;
			#clock-cells = <0x00>;
			extcon,ignore-usb;
			compatible = "rockchip,rk3399-usb2phy";
			status = "okay";
			reg = <0xe450 0x10>;
			phandle = <0x2a>;

			port {

				endpoint {
					remote-endpoint = <0x90>;
					phandle = <0x82>;
				};
			};

			host-port {
				phy-supply = <0x8f>;
				interrupts = <0x00 0x1b 0x04 0x00>;
				#phy-cells = <0x00>;
				status = "okay";
				interrupt-names = "linestate";
				phandle = <0x2b>;
			};

			otg-port {
				interrupts = <0x00 0x67 0x04 0x00 0x00 0x68 0x04 0x00 0x00 0x6a 0x04 0x00>;
				#phy-cells = <0x00>;
				status = "okay";
				interrupt-names = "otg-bvalid", "otg-id", "linestate";
				phandle = <0x2e>;
			};
		};

		io-domains {
			compatible = "rockchip,rk3399-io-voltage-domain";
			status = "disabled";
			phandle = <0x10f>;
		};

		phy@f780 {
			clock-names = "emmcclk";
			clocks = <0x91>;
			drive-impedance-ohm = <0x32>;
			#phy-cells = <0x00>;
			compatible = "rockchip,rk3399-emmc-phy";
			status = "okay";
			reg = <0xf780 0x24>;
			phandle = <0x29>;
		};
	};

	efuse@ff690000 {
		#address-cells = <0x01>;
		clock-names = "pclk_efuse";
		clocks = <0x08 0x17d>;
		#size-cells = <0x01>;
		compatible = "rockchip,rk3399-efuse";
		reg = <0x00 0xff690000 0x00 0x80>;
		phandle = <0x107>;

		cpu-leakage@1a {
			reg = <0x1a 0x01>;
			phandle = <0x10c>;
		};

		center-leakage@19 {
			reg = <0x19 0x01>;
			phandle = <0x10b>;
		};

		logic-leakage@1b {
			reg = <0x1b 0x01>;
			phandle = <0x10d>;
		};

		cpu-id@7 {
			reg = <0x07 0x10>;
			phandle = <0x108>;
		};

		gpu-leakage@18 {
			reg = <0x18 0x01>;
			phandle = <0x10a>;
		};

		wafer-info@1c {
			reg = <0x1c 0x01>;
			phandle = <0x10e>;
		};

		cpu-leakage@17 {
			reg = <0x17 0x01>;
			phandle = <0x109>;
		};
	};

	qos@ffa70080 {
		compatible = "rockchip,rk3399-qos", "syscon";
		reg = <0x00 0xffa70080 0x00 0x20>;
		phandle = <0x69>;
	};

	xin32k {
		clock-output-names = "xin32k";
		#clock-cells = <0x00>;
		clock-frequency = <0x8000>;
		compatible = "fixed-clock";
		phandle = <0x164>;
	};

	interrupt-controller@fee00000 {
		#address-cells = <0x02>;
		interrupts = <0x01 0x09 0x04 0x00>;
		#size-cells = <0x02>;
		compatible = "arm,gic-v3";
		ranges;
		#interrupt-cells = <0x04>;
		reg = <0x00 0xfee00000 0x00 0x10000 0x00 0xfef00000 0x00 0xc0000 0x00 0xfff00000 0x00 0x10000 0x00 0xfff10000 0x00 0x10000 0x00 0xfff20000 0x00 0x10000>;
		phandle = <0x01>;
		interrupt-controller;

		ppi-partitions {

			interrupt-partition-0 {
				affinity = <0x02 0x03 0x04 0x05>;
				phandle = <0x16>;
			};

			interrupt-partition-1 {
				affinity = <0x06 0x07>;
				phandle = <0x17>;
			};
		};

		msi-controller@fee20000 {
			msi-controller;
			compatible = "arm,gic-v3-its";
			reg = <0x00 0xfee20000 0x00 0x20000>;
			phandle = <0x19>;
			#msi-cells = <0x01>;
		};
	};

	i2c@ff160000 {
		pinctrl-names = "default";
		#address-cells = <0x01>;
		pinctrl-0 = <0x3b>;
		clock-names = "i2c", "pclk";
		assigned-clocks = <0x08 0x46>;
		assigned-clock-rates = <0xbebc200>;
		interrupts = <0x00 0x24 0x04 0x00>;
		clocks = <0x08 0x46 0x08 0x15a>;
		#size-cells = <0x00>;
		compatible = "rockchip,rk3399-i2c";
		status = "disabled";
		reg = <0x00 0xff160000 0x00 0x1000>;
		phandle = <0xd9>;
	};

	qos@ffa98000 {
		compatible = "rockchip,rk3399-qos", "syscon";
		reg = <0x00 0xffa98000 0x00 0x20>;
		phandle = <0x5d>;
	};

	display-subsystem {
		ports = <0x11 0x12>;
		compatible = "rockchip,display-subsystem";
	};

	dp@fec00000 {
		power-domains = <0x1e 0x15>;
		clock-names = "core-clk", "pclk", "spdif", "grf";
		assigned-clocks = <0x08 0x72 0x08 0xa1>;
		assigned-clock-rates = <0x5f5e100 0xbebc200>;
		resets = <0x08 0x103 0x08 0x148 0x08 0x14a 0x08 0xfd>;
		interrupts = <0x00 0x09 0x04 0x00>;
		clocks = <0x08 0x72 0x08 0x175 0x08 0xa1 0x08 0x16f>;
		extcon = <0x30>;
		#sound-dai-cells = <0x01>;
		compatible = "rockchip,rk3399-cdn-dp";
		status = "okay";
		rockchip,grf = <0x1f>;
		phys = <0x33>;
		reg = <0x00 0xfec00000 0x00 0x100000>;
		phandle = <0xd0>;
		reset-names = "spdif", "dptx", "apb", "core";

		ports {

			port {
				#address-cells = <0x01>;
				#size-cells = <0x00>;
				phandle = <0xd1>;

				endpoint@1 {
					remote-endpoint = <0x35>;
					reg = <0x01>;
					phandle = <0x9d>;
				};

				endpoint@0 {
					remote-endpoint = <0x34>;
					reg = <0x00>;
					phandle = <0xa3>;
				};
			};
		};
	};

	vcc-lcd {
		regulator-max-microvolt = <0x325aa0>;
		regulator-boot-on;
		gpio = <0xbc 0x1e 0x00>;
		enable-active-high;
		regulator-min-microvolt = <0x325aa0>;
		regulator-name = "vcc_lcd";
		startup-delay-us = <0x4e20>;
		compatible = "regulator-fixed";
		phandle = <0x162>;
		vin-supply = <0x7d>;
	};

	gpio-leds {
		compatible = "gpio-leds";

		pwr-led {
			linux,default-trigger = "default-on";
			color = <0x01>;
			retain-state-suspended = <0x01>;
			gpios = <0x1b 0x04 0x00>;
		};

		rsv-led {
			linux,default-trigger = "heartbeat";
			color = <0x06>;
			gpios = <0x1b 0x0a 0x00>;
		};

		act-led {
			linux,default-trigger = "mmc0";
			color = <0x02>;
			gpios = <0x1b 0x03 0x00>;
		};
	};

	iommu@ff670800 {
		power-domains = <0x1e 0x22>;
		clock-names = "aclk", "iface";
		interrupts = <0x00 0x2a 0x04 0x00>;
		clocks = <0x08 0xe1 0x08 0x1dd>;
		#iommu-cells = <0x00>;
		compatible = "rockchip,iommu";
		reg = <0x00 0xff670800 0x00 0x40>;
		phandle = <0x8d>;
	};

	spi@ff1e0000 {
		pinctrl-names = "default";
		#address-cells = <0x01>;
		pinctrl-0 = <0x49 0x4a 0x4b 0x4c>;
		clock-names = "spiclk", "apb_pclk";
		interrupts = <0x00 0x34 0x04 0x00>;
		clocks = <0x08 0x49 0x08 0x15d>;
		#size-cells = <0x00>;
		dma-names = "tx", "rx";
		compatible = "rockchip,rk3399-spi", "rockchip,rk3066-spi";
		status = "disabled";
		reg = <0x00 0xff1e0000 0x00 0x1000>;
		phandle = <0xe0>;
		dmas = <0x40 0x0e 0x40 0x0f>;
	};

	vcc5v0-host-regulator {
		pinctrl-names = "default";
		gpio = <0xbc 0x19 0x00>;
		pinctrl-0 = <0xbf>;
		enable-active-high;
		regulator-name = "vcc5v0_host";
		compatible = "regulator-fixed";
		phandle = <0x8f>;
		vin-supply = <0x7d>;
	};

	rga@ff680000 {
		power-domains = <0x1e 0x21>;
		clock-names = "aclk", "hclk", "sclk";
		resets = <0x08 0x6a 0x08 0x67 0x08 0x69>;
		interrupts = <0x00 0x37 0x04 0x00>;
		clocks = <0x08 0xdc 0x08 0x1e5 0x08 0x6d>;
		compatible = "rockchip,rk3399-rga";
		reg = <0x00 0xff680000 0x00 0x10000>;
		phandle = <0x106>;
		reset-names = "core", "axi", "ahb";
	};

	i2s@ff890000 {
		power-domains = <0x1e 0x1c>;
		pinctrl-names = "default";
		pinctrl-0 = <0x97>;
		clock-names = "i2s_clk", "i2s_hclk";
		interrupts = <0x00 0x28 0x04 0x00>;
		clocks = <0x08 0x57 0x08 0x1d5>;
		dma-names = "tx", "rx";
		#sound-dai-cells = <0x00>;
		compatible = "rockchip,rk3399-i2s", "rockchip,rk3066-i2s";
		status = "disabled";
		reg = <0x00 0xff890000 0x00 0x1000>;
		phandle = <0x116>;
		dmas = <0x51 0x02 0x51 0x03>;
	};

	thermal-zones {
		phandle = <0xe3>;

		cpu-thermal {
			polling-delay = <0x3e8>;
			polling-delay-passive = <0x64>;
			thermal-sensors = <0x56 0x00>;
			phandle = <0xe4>;

			trips {

				cpu_crit {
					temperature = <0x186a0>;
					hysteresis = <0x7d0>;
					type = "critical";
					phandle = <0xe5>;
				};

				cpu_alert0 {
					temperature = <0x14c08>;
					hysteresis = <0x7d0>;
					type = "passive";
					phandle = <0x57>;
				};

				cpu_alert1 {
					temperature = <0x17318>;
					hysteresis = <0x7d0>;
					type = "passive";
					phandle = <0x58>;
				};
			};

			cooling-maps {

				map0 {
					trip = <0x57>;
					cooling-device = <0x06 0xffffffff 0xffffffff 0x07 0xffffffff 0xffffffff>;
				};

				map1 {
					trip = <0x58>;
					cooling-device = <0x02 0xffffffff 0xffffffff 0x03 0xffffffff 0xffffffff 0x04 0xffffffff 0xffffffff 0x05 0xffffffff 0xffffffff 0x06 0xffffffff 0xffffffff 0x07 0xffffffff 0xffffffff>;
				};
			};
		};

		gpu-thermal {
			polling-delay = <0x3e8>;
			polling-delay-passive = <0x64>;
			thermal-sensors = <0x56 0x01>;
			phandle = <0xe6>;

			trips {

				gpu_alert0 {
					temperature = <0x124f8>;
					hysteresis = <0x7d0>;
					type = "passive";
					phandle = <0x59>;
				};

				gpu_crit {
					temperature = <0x17318>;
					hysteresis = <0x7d0>;
					type = "critical";
					phandle = <0xe7>;
				};
			};

			cooling-maps {

				map0 {
					trip = <0x59>;
					cooling-device = <0x5a 0xffffffff 0xffffffff>;
				};
			};
		};
	};

	isp1@ff920000 {
		power-domains = <0x1e 0x14>;
		iommus = <0xa6>;
		phy-names = "dphy";
		clock-names = "isp", "aclk", "hclk";
		interrupts = <0x00 0x2c 0x04 0x00>;
		clocks = <0x08 0x6f 0x08 0xea 0x08 0x1e4>;
		compatible = "rockchip,rk3399-cif-isp";
		status = "disabled";
		phys = <0xa7>;
		reg = <0x00 0xff920000 0x00 0x4000>;
		phandle = <0x11a>;

		ports {
			#address-cells = <0x01>;
			#size-cells = <0x00>;

			port@0 {
				#address-cells = <0x01>;
				#size-cells = <0x00>;
				reg = <0x00>;
			};
		};
	};

	video-codec@ff650000 {
		power-domains = <0x1e 0x1f>;
		iommus = <0x8b>;
		clock-names = "aclk", "hclk";
		interrupts = <0x00 0x72 0x04 0x00 0x00 0x71 0x04 0x00>;
		clocks = <0x08 0xeb 0x08 0x1ea>;
		compatible = "rockchip,rk3399-vpu";
		interrupt-names = "vepu", "vdpu";
		reg = <0x00 0xff650000 0x00 0x800>;
		phandle = <0x103>;
	};

	pmu_a72 {
		interrupts = <0x01 0x07 0x08 0x17>;
		compatible = "arm,cortex-a72-pmu";
	};

	vcc5v0-sys {
		regulator-max-microvolt = <0x4c4b40>;
		regulator-boot-on;
		regulator-always-on;
		regulator-min-microvolt = <0x4c4b40>;
		regulator-name = "vcc5v0_sys";
		compatible = "regulator-fixed";
		phandle = <0x7d>;
	};

	iommu@ff914000 {
		power-domains = <0x1e 0x13>;
		clock-names = "aclk", "iface";
		interrupts = <0x00 0x2b 0x04 0x00>;
		clocks = <0x08 0xe9 0x08 0x1e3>;
		#iommu-cells = <0x00>;
		compatible = "rockchip,iommu";
		rockchip,disable-mmu-reset;
		reg = <0x00 0xff914000 0x00 0x100 0x00 0xff915000 0x00 0x100>;
		phandle = <0xa4>;
	};

	qos@ffaa0000 {
		compatible = "rockchip,rk3399-qos", "syscon";
		reg = <0x00 0xffaa0000 0x00 0x20>;
		phandle = <0x6b>;
	};

	crypto@ff8b0000 {
		clock-names = "hclk_master", "hclk_slave", "sclk";
		resets = <0x08 0xb5 0x08 0xae 0x08 0xaf>;
		interrupts = <0x00 0x00 0x04 0x00>;
		clocks = <0x08 0x1d0 0x08 0x1d2 0x08 0x85>;
		compatible = "rockchip,rk3399-crypto";
		reg = <0x00 0xff8b0000 0x00 0x4000>;
		phandle = <0xd3>;
		reset-names = "master", "slave", "crypto-rst";
	};

	psci {
		method = "smc";
		compatible = "arm,psci-1.0";
	};

	xin24m {
		clock-output-names = "xin24m";
		#clock-cells = <0x00>;
		clock-frequency = <0x16e3600>;
		compatible = "fixed-clock";
		phandle = <0x8e>;
	};

	spi@ff200000 {
		power-domains = <0x1e 0x1c>;
		pinctrl-names = "default";
		#address-cells = <0x01>;
		pinctrl-0 = <0x52 0x53 0x54 0x55>;
		clock-names = "spiclk", "apb_pclk";
		interrupts = <0x00 0x84 0x04 0x00>;
		clocks = <0x08 0x4b 0x08 0x15f>;
		#size-cells = <0x00>;
		dma-names = "tx", "rx";
		compatible = "rockchip,rk3399-spi", "rockchip,rk3066-spi";
		status = "disabled";
		reg = <0x00 0xff200000 0x00 0x1000>;
		phandle = <0xe2>;
		dmas = <0x51 0x08 0x51 0x09>;
	};

	dp@ff970000 {
		power-domains = <0x1e 0x19>;
		pinctrl-names = "default";
		pinctrl-0 = <0xb1>;
		clock-names = "dp", "pclk", "grf";
		resets = <0x08 0x11d>;
		interrupts = <0x00 0x0a 0x04 0x00>;
		clocks = <0x08 0x16a 0x08 0x16c 0x08 0x16f>;
		compatible = "rockchip,rk3399-edp";
		status = "disabled";
		rockchip,grf = <0x1f>;
		reg = <0x00 0xff970000 0x00 0x8000>;
		phandle = <0x123>;
		reset-names = "dp";

		ports {
			#address-cells = <0x01>;
			#size-cells = <0x00>;

			port@0 {
				#address-cells = <0x01>;
				#size-cells = <0x00>;
				reg = <0x00>;
				phandle = <0x124>;

				endpoint@1 {
					remote-endpoint = <0xb3>;
					reg = <0x01>;
					phandle = <0x9a>;
				};

				endpoint@0 {
					remote-endpoint = <0xb2>;
					reg = <0x00>;
					phandle = <0x9f>;
				};
			};

			port@1 {
				reg = <0x01>;
				phandle = <0x125>;
			};
		};
	};

	qos@ffae0000 {
		compatible = "rockchip,rk3399-qos", "syscon";
		reg = <0x00 0xffae0000 0x00 0x20>;
		phandle = <0x63>;
	};

	vdd-log {
		regulator-max-microvolt = <0x155cc0>;
		regulator-boot-on;
		regulator-always-on;
		rockchip,pwm_voltage = <0xdbba0>;
		regulator-min-microvolt = "", "\f5";
		regulator-name = "vdd_log";
		compatible = "pwm-regulator";
		rockchip,pwm_id = <0x02>;
		phandle = <0x163>;
		pwms = <0xc1 0x00 0x61a8 0x01>;
	};

	qos@ffab0080 {
		compatible = "rockchip,rk3399-qos", "syscon";
		reg = <0x00 0xffab0080 0x00 0x20>;
		phandle = <0x5f>;
	};

	iommu@ff903f00 {
		power-domains = <0x1e 0x11>;
		clock-names = "aclk", "iface";
		interrupts = <0x00 0x76 0x04 0x00>;
		clocks = <0x08 0xd9 0x08 0x1d9>;
		#iommu-cells = <0x00>;
		compatible = "rockchip,iommu";
		status = "okay";
		reg = <0x00 0xff903f00 0x00 0x100>;
		phandle = <0x9e>;
	};

	dsi@ff960000 {
		power-domains = <0x1e 0x0f>;
		clock-names = "ref", "pclk", "phy_cfg", "grf";
		resets = <0x08 0xfb>;
		interrupts = <0x00 0x2d 0x04 0x00>;
		clocks = <0x08 0xa2 0x08 0x170 0x08 0xa3 0x08 0x16f>;
		compatible = "rockchip,rk3399-mipi-dsi", "snps,dw-mipi-dsi";
		status = "disabled";
		rockchip,grf = <0x1f>;
		reg = <0x00 0xff960000 0x00 0x8000>;
		phandle = <0x11e>;
		reset-names = "apb";

		ports {
			#address-cells = <0x01>;
			#size-cells = <0x00>;

			port@0 {
				#address-cells = <0x01>;
				#size-cells = <0x00>;
				reg = <0x00>;
				phandle = <0x11f>;

				endpoint@1 {
					remote-endpoint = <0xae>;
					reg = <0x01>;
					phandle = <0x99>;
				};

				endpoint@0 {
					remote-endpoint = <0xad>;
					reg = <0x00>;
					phandle = <0xa0>;
				};
			};

			port@1 {
				reg = <0x01>;
				phandle = <0x120>;
			};
		};
	};

	qos@ffa76000 {
		compatible = "rockchip,rk3399-qos", "syscon";
		reg = <0x00 0xffa76000 0x00 0x20>;
		phandle = <0x67>;
	};

	serial@ff1b0000 {
		reg-io-width = <0x04>;
		pinctrl-names = "default";
		pinctrl-0 = <0x3f>;
		clock-names = "baudclk", "apb_pclk";
		interrupts = <0x00 0x65 0x04 0x00>;
		clocks = <0x08 0x54 0x08 0x163>;
		compatible = "rockchip,rk3399-uart", "snps,dw-apb-uart";
		status = "disabled";
		reg = <0x00 0xff1b0000 0x00 0x100>;
		phandle = <0xdd>;
		reg-shift = <0x02>;
	};

	watchdog@ff848000 {
		resets = <0x08 0x145>;
		interrupts = <0x00 0x78 0x04 0x00>;
		clocks = <0x08 0x17c>;
		compatible = "rockchip,rk3399-wdt", "snps,dw-wdt";
		reg = <0x00 0xff848000 0x00 0x100>;
	};

	qos@ffaa8080 {
		compatible = "rockchip,rk3399-qos", "syscon";
		reg = <0x00 0xffaa8080 0x00 0x20>;
		phandle = <0x6e>;
	};

	board-info {
		pid-id2 = <0xbd 0x02 0x00>;
		pid-id0 = <0xbd 0x05 0x00>;
		ddr-id2 = <0xbc 0x00 0x00>;
		hw-id2 = <0xbc 0x05 0x00>;
		hw-id0 = <0xbc 0x07 0x00>;
		pid-id1 = <0xbd 0x03 0x00>;
		compatible = "board-info";
		ddr-id1 = <0xbc 0x04 0x00>;
		pmic-reset = <0x79 0x06 0x00>;
		phandle = <0x15f>;
		hw-id1 = <0xbc 0x06 0x00>;
	};

	qos@ffa70000 {
		compatible = "rockchip,rk3399-qos", "syscon";
		reg = <0x00 0xffa70000 0x00 0x20>;
		phandle = <0x68>;
	};

	i2c@ff130000 {
		pinctrl-names = "default";
		#address-cells = <0x01>;
		pinctrl-0 = <0x38>;
		clock-names = "i2c", "pclk";
		assigned-clocks = <0x08 0x43>;
		assigned-clock-rates = <0xbebc200>;
		interrupts = <0x00 0x22 0x04 0x00>;
		clocks = <0x08 0x43 0x08 0x157>;
		#size-cells = <0x00>;
		compatible = "rockchip,rk3399-i2c";
		status = "okay";
		reg = <0x00 0xff130000 0x00 0x1000>;
		phandle = <0xaa>;
	};

	mmc@fe330000 {
		power-domains = <0x1e 0x17>;
		disable-cqe-dcmd;
		clock-output-names = "emmc_cardclock";
		phy-names = "phy_arasan";
		clock-names = "clk_xin", "clk_ahb";
		assigned-clocks = <0x08 0x4e>;
		mmc-hs200-1_8v;
		bus-width = <0x08>;
		non-removable;
		assigned-clock-rates = <0xbebc200>;
		interrupts = <0x00 0x0b 0x04 0x00>;
		clocks = <0x08 0x4e 0x08 0xf0>;
		arasan,soc-ctl-syscon = <0x1f>;
		#clock-cells = <0x00>;
		keep-power-in-suspend;
		compatible = "rockchip,rk3399-sdhci-5.1", "arasan,sdhci-5.1";
		status = "okay";
		phys = <0x29>;
		reg = <0x00 0xfe330000 0x00 0x10000>;
		phandle = <0x91>;
		supports-emmc;
	};

	gpio-fan {
		pinctrl-names = "default";
		pinctrl-0 = <0xbe>;
		gpio-fan,speed-map = <0x32 0x00 0x64 0x01>;
		compatible = "gpio-fan";
		phandle = <0x161>;
		gpios = <0xbc 0x1a 0x00>;
		#cooling-cells = <0x02>;
		fan-supply = <0x7d>;
	};

	opp-table-2 {
		compatible = "operating-points-v2";
		phandle = <0xb4>;

		opp04 {
			opp-microvolt = <0xe1d48 0xe1d48 0x106738>;
			opp-hz = <0x00 0x23c34600>;
		};

		opp02 {
			opp-microvolt = <0xc96a8 0xc96a8 0x106738>;
			opp-hz = <0x00 0x17d78400>;
		};

		opp00 {
			opp-microvolt = <0xc3500 0xc3500 0x106738>;
			opp-hz = <0x00 0xbebc200>;
		};

		opp05 {
			opp-microvolt = <0x106738 0x106738 0x106738>;
			opp-hz = <0x00 0x2faf0800>;
		};

		opp03 {
			opp-microvolt = <0xcf850 0xcf850 0x106738>;
			opp-hz = <0x00 0x1dcd6500>;
		};

		opp01 {
			opp-microvolt = <0xc3500 0xc3500 0x106738>;
			opp-hz = <0x00 0x11b3dc40>;
		};
	};

	tsadc@ff260000 {
		pinctrl-names = "init", "default", "sleep";
		pinctrl-2 = <0x5b>;
		pinctrl-0 = <0x5b>;
		clock-names = "tsadc", "apb_pclk";
		rockchip,hw-tshut-polarity = <0x01>;
		assigned-clocks = <0x08 0x4f>;
		assigned-clock-rates = <0xb71b0>;
		resets = <0x08 0xe8>;
		interrupts = <0x00 0x61 0x04 0x00>;
		rockchip,hw-tshut-mode = <0x01>;
		clocks = <0x08 0x4f 0x08 0x164>;
		#thermal-sensor-cells = <0x01>;
		compatible = "rockchip,rk3399-tsadc";
		pinctrl-1 = <0x5c>;
		status = "okay";
		rockchip,grf = <0x1f>;
		reg = <0x00 0xff260000 0x00 0x100>;
		phandle = <0x56>;
		reset-names = "tsadc-apb";
		rockchip,hw-tshut-temp = <0x17318>;
	};

	usb@fe900000 {
		#address-cells = <0x02>;
		clock-names = "ref_clk", "suspend_clk", "bus_clk", "aclk_usb3_rksoc_axi_perf", "aclk_usb3", "grf_clk";
		resets = <0x08 0x126>;
		clocks = <0x08 0x82 0x08 0x84 0x08 0xf7 0x08 0xf8 0x08 0xf4 0x08 0xf9>;
		#size-cells = <0x02>;
		compatible = "rockchip,rk3399-dwc3";
		ranges;
		status = "okay";
		phandle = <0xce>;
		reset-names = "usb3-otg";

		usb@fe900000 {
			power-domains = <0x1e 0x18>;
			snps,dis_enblslpm_quirk;
			phy-names = "usb2-phy", "usb3-phy";
			clock-names = "ref", "bus_early", "suspend";
			snps,dis-u2-freeclk-exists-quirk;
			phy_type = "utmi_wide";
			snps,dis_u2_susphy_quirk;
			interrupts = <0x00 0x6e 0x04 0x00>;
			clocks = <0x08 0x82 0x08 0xf7 0x08 0x84>;
			compatible = "snps,dwc3";
			snps,dis-del-phy-power-chg-quirk;
			status = "okay";
			snps,xhci-trb-ent-quirk;
			phys = <0x31 0x32>;
			reg = <0x00 0xfe900000 0x00 0x100000>;
			phandle = <0xcf>;
			dr_mode = "host";
			snps,dis-tx-ipgap-linecheck-quirk;
		};
	};

	serial@ff180000 {
		reg-io-width = <0x04>;
		pinctrl-names = "default";
		pinctrl-0 = <0x3c>;
		clock-names = "baudclk", "apb_pclk";
		interrupts = <0x00 0x63 0x04 0x00>;
		clocks = <0x08 0x51 0x08 0x160>;
		compatible = "rockchip,rk3399-uart", "snps,dw-apb-uart";
		status = "disabled";
		reg = <0x00 0xff180000 0x00 0x100>;
		phandle = <0xda>;
		reg-shift = <0x02>;
	};

	usb@fe380000 {
		phy-names = "usb";
		interrupts = <0x00 0x1a 0x04 0x00>;
		clocks = <0x08 0x1c8 0x08 0x1c9 0x2a>;
		compatible = "generic-ehci";
		status = "okay";
		phys = <0x2b>;
		reg = <0x00 0xfe380000 0x00 0x20000>;
		phandle = <0xc8>;
	};

	ethernet@fe300000 {
		power-domains = <0x1e 0x16>;
		pinctrl-names = "default";
		phy-supply = <0x20>;
		phy-mode = "rgmii";
		snps,txpbl = <0x04>;
		snps,reset-active-low;
		pinctrl-0 = <0x21>;
		clock-names = "stmmaceth", "mac_clk_rx", "mac_clk_tx", "clk_mac_ref", "clk_mac_refout", "aclk_mac", "pclk_mac";
		assigned-clocks = <0x08 0xa6>;
		assigned-clock-parents = <0x08 0x69>;
		assigned-clock-rates = <0x7735940>;
		resets = <0x08 0x89>;
		interrupts = <0x00 0x0c 0x04 0x00>;
		clocks = <0x08 0x69 0x08 0x67 0x08 0x68 0x08 0x66 0x08 0x6a 0x08 0xd5 0x08 0x166>;
		clock_in_out = "input";
		compatible = "rockchip,rk3399-gmac";
		status = "okay";
		rockchip,grf = <0x1f>;
		interrupt-names = "macirq";
		snps,reset-gpio = <0x22 0x0f 0x01>;
		reg = <0x00 0xfe300000 0x00 0x10000>;
		rx_delay = <0x20>;
		phandle = <0xc5>;
		reset-names = "stmmaceth";
		tx_delay = <0x25>;
		snps,reset-delays-us = <0x00 0x3e80 0x11940>;
		wakeup-enable = "0";
	};

	debug@fe434000 {
		clock-names = "apb_pclk";
		clocks = <0x08 0x14d>;
		cpu = <0x04>;
		compatible = "arm,coresight-cpu-debug", "arm,primecell";
		reg = <0x00 0xfe434000 0x00 0x1000>;
	};

	spi@ff350000 {
		pinctrl-names = "default";
		#address-cells = <0x01>;
		pinctrl-0 = <0x73 0x74 0x75 0x76>;
		clock-names = "spiclk", "apb_pclk";
		interrupts = <0x00 0x3c 0x04 0x00>;
		clocks = <0x72 0x03 0x72 0x1f>;
		#size-cells = <0x00>;
		compatible = "rockchip,rk3399-spi", "rockchip,rk3066-spi";
		status = "disabled";
		reg = <0x00 0xff350000 0x00 0x1000>;
		phandle = <0xee>;
	};

	vcc-phy-regulator {
		regulator-boot-on;
		regulator-always-on;
		regulator-name = "vcc_phy";
		compatible = "regulator-fixed";
		phandle = <0x20>;
	};

	vcc3v3-sys {
		regulator-max-microvolt = <0x325aa0>;
		regulator-boot-on;
		regulator-always-on;
		regulator-min-microvolt = <0x325aa0>;
		regulator-name = "vcc3v3_sys";
		compatible = "regulator-fixed";
		phandle = <0x7b>;
	};

	spi@ff1f0000 {
		pinctrl-names = "default";
		#address-cells = <0x01>;
		pinctrl-0 = <0x4d 0x4e 0x4f 0x50>;
		clock-names = "spiclk", "apb_pclk";
		interrupts = <0x00 0x43 0x04 0x00>;
		clocks = <0x08 0x4a 0x08 0x15e>;
		#size-cells = <0x00>;
		dma-names = "tx", "rx";
		compatible = "rockchip,rk3399-spi", "rockchip,rk3066-spi";
		status = "disabled";
		reg = <0x00 0xff1f0000 0x00 0x1000>;
		phandle = <0xe1>;
		dmas = <0x40 0x12 0x40 0x13>;
	};

	syscon@ff320000 {
		compatible = "rockchip,rk3399-pmugrf", "syscon", "simple-mfd";
		reg = <0x00 0xff320000 0x00 0x1000>;
		phandle = <0x13>;

		io-domains {
			compatible = "rockchip,rk3399-pmu-io-voltage-domain";
			status = "disabled";
			phandle = <0xed>;
		};
	};

	iommu@ff8f3f00 {
		power-domains = <0x1e 0x12>;
		clock-names = "aclk", "iface";
		interrupts = <0x00 0x77 0x04 0x00>;
		clocks = <0x08 0xdb 0x08 0x1db>;
		#iommu-cells = <0x00>;
		compatible = "rockchip,iommu";
		status = "okay";
		reg = <0x00 0xff8f3f00 0x00 0x100>;
		phandle = <0x98>;
	};

	timer {
		arm,no-tick-in-suspend;
		interrupts = <0x01 0x0d 0x08 0x00 0x01 0x0e 0x08 0x00 0x01 0x0b 0x08 0x00 0x01 0x0a 0x08 0x00>;
		compatible = "arm,armv8-timer";
	};

	video-codec@ff660000 {
		power-domains = <0x1e 0x20>;
		iommus = <0x8c>;
		clock-names = "axi", "ahb", "cabac", "core";
		interrupts = <0x00 0x74 0x04 0x00>;
		clocks = <0x08 0xed 0x08 0x1ec 0x08 0x9f 0x08 0x9e>;
		compatible = "rockchip,rk3399-vdec";
		reg = <0x00 0xff660000 0x00 0x480>;
		phandle = <0x104>;
	};

	opp-table-0 {
		opp-shared;
		compatible = "operating-points-v2";
		phandle = <0x0c>;

		opp04 {
			opp-microvolt = <0xee098 0xee098 0x118c30>;
			opp-hz = <0x00 0x47868c00>;
		};

		opp02 {
			opp-microvolt = <0xcf850 0xcf850 0x118c30>;
			opp-hz = <0x00 0x30a32c00>;
		};

		opp00 {
			opp-microvolt = <0xc3500 0xc3500 0x118c30>;
			opp-hz = <0x00 0x18519600>;
			clock-latency-ns = <0x9c40>;
		};

		opp05 {
			opp-microvolt = <0x10c8e0 0x10c8e0 0x118c30>;
			opp-hz = <0x00 0x54667200>;
		};

		opp03 {
			opp-microvolt = <0xdbba0 0xdbba0 0x118c30>;
			opp-hz = <0x00 0x3c14dc00>;
		};

		opp01 {
			opp-microvolt = <0xc96a8 0xc96a8 0x118c30>;
			opp-hz = <0x00 0x23c34600>;
		};

		opp06 {
			opp-microvolt = <0x118c30 0x118c30 0x118c30>;
			opp-hz = <0x00 0x5a1f4a00>;
		};
	};

	iommu@ff924000 {
		power-domains = <0x1e 0x14>;
		clock-names = "aclk", "iface";
		interrupts = <0x00 0x2c 0x04 0x00>;
		clocks = <0x08 0xea 0x08 0x1e4>;
		#iommu-cells = <0x00>;
		compatible = "rockchip,iommu";
		rockchip,disable-mmu-reset;
		reg = <0x00 0xff924000 0x00 0x100 0x00 0xff925000 0x00 0x100>;
		phandle = <0xa6>;
	};

	i2c@ff3c0000 {
		pinctrl-names = "default";
		#address-cells = <0x01>;
		pinctrl-0 = <0x78>;
		clock-names = "i2c", "pclk";
		assigned-clocks = <0x72 0x09>;
		assigned-clock-rates = <0xbebc200>;
		interrupts = <0x00 0x39 0x04 0x00>;
		clocks = <0x72 0x09 0x72 0x1b>;
		#size-cells = <0x00>;
		compatible = "rockchip,rk3399-i2c";
		status = "okay";
		reg = <0x00 0xff3c0000 0x00 0x1000>;
		phandle = <0xf0>;

		pmic@1b {
			system-power-controller;
			vcc11-supply = <0x7b>;
			pinctrl-names = "default";
			vcc12-supply = <0x7b>;
			clock-output-names = "rk808-clkout1", "rk808-clkout2";
			pinctrl-0 = <0x7a>;
			wakeup-source;
			interrupts = <0x12 0x08>;
			#clock-cells = <0x01>;
			interrupt-parent = <0x79>;
			vcc1-supply = <0x7b>;
			vcc2-supply = <0x7b>;
			compatible = "rockchip,rk808";
			vddio-supply = <0x7c>;
			vcc3-supply = <0x7b>;
			vcc4-supply = <0x7b>;
			reg = <0x1b>;
			phandle = <0xf1>;
			vcc6-supply = <0x7b>;
			vcc7-supply = <0x7b>;
			vcc8-supply = <0x7b>;
			vcc9-supply = <0x7b>;
			vcc10-supply = <0x7b>;

			regulators {

				DCDC_REG4 {
					regulator-max-microvolt = <0x1b7740>;
					regulator-boot-on;
					regulator-always-on;
					regulator-min-microvolt = <0x1b7740>;
					regulator-name = "vcc_1v8";
					phandle = <0xf4>;

					regulator-state-mem {
						regulator-suspend-microvolt = <0x1b7740>;
						regulator-on-in-suspend;
					};
				};

				LDO_REG4 {
					regulator-max-microvolt = <0x325aa0>;
					regulator-boot-on;
					regulator-always-on;
					regulator-min-microvolt = <0x1b7740>;
					regulator-name = "vccio_sd";
					phandle = <0x24>;

					regulator-state-mem {
						regulator-suspend-microvolt = <0x2dc6c0>;
						regulator-on-in-suspend;
					};
				};

				DCDC_REG2 {
					regulator-max-microvolt = <0x149970>;
					regulator-boot-on;
					regulator-always-on;
					regulator-min-microvolt = <0xb71b0>;
					regulator-name = "vdd_cpu_l";
					regulator-ramp-delay = <0x1771>;
					phandle = <0x0d>;

					regulator-state-mem {
						regulator-off-in-suspend;
					};
				};

				LDO_REG2 {
					regulator-max-microvolt = <0x1b7740>;
					regulator-boot-on;
					regulator-always-on;
					regulator-min-microvolt = <0x1b7740>;
					regulator-name = "vcca1v8_hdmi";
					phandle = <0xf6>;

					regulator-state-mem {
						regulator-off-in-suspend;
					};
				};

				SWITCH_REG1 {
					regulator-boot-on;
					regulator-always-on;
					regulator-name = "vcc3v3_s3";
					phandle = <0x23>;

					regulator-state-mem {
						regulator-on-in-suspend;
					};
				};

				LDO_REG7 {
					regulator-max-microvolt = <0xdbba0>;
					regulator-boot-on;
					regulator-always-on;
					regulator-min-microvolt = <0xdbba0>;
					regulator-name = "vcca0v9_hdmi";
					phandle = <0xf9>;

					regulator-state-mem {
						regulator-off-in-suspend;
					};
				};

				LDO_REG5 {
					regulator-max-microvolt = <0x325aa0>;
					regulator-boot-on;
					regulator-always-on;
					regulator-min-microvolt = <0x325aa0>;
					regulator-name = "vcc3v3_csi";
					phandle = <0xf7>;

					regulator-state-mem {
						regulator-off-in-suspend;
					};
				};

				DCDC_REG3 {
					regulator-boot-on;
					regulator-always-on;
					regulator-name = "vcc_ddr";
					phandle = <0xf3>;

					regulator-state-mem {
						regulator-on-in-suspend;
					};
				};

				LDO_REG3 {
					regulator-max-microvolt = <0x1b7740>;
					regulator-boot-on;
					regulator-always-on;
					regulator-min-microvolt = <0x1b7740>;
					regulator-name = "vcc1v8_pmu";
					phandle = <0x7c>;

					regulator-state-mem {
						regulator-suspend-microvolt = <0x1b7740>;
						regulator-on-in-suspend;
					};
				};

				DCDC_REG1 {
					regulator-max-microvolt = <0x149970>;
					regulator-boot-on;
					regulator-always-on;
					regulator-min-microvolt = <0xb71b0>;
					regulator-name = "vdd_center";
					regulator-ramp-delay = <0x1771>;
					phandle = <0xf2>;

					regulator-state-mem {
						regulator-suspend-microvolt = <0xdbba0>;
						regulator-on-in-suspend;
					};
				};

				LDO_REG1 {
					regulator-max-microvolt = <0x325aa0>;
					regulator-boot-on;
					regulator-always-on;
					regulator-min-microvolt = <0x325aa0>;
					regulator-name = "vcc3v3_dsi";
					phandle = <0xf5>;

					regulator-state-mem {
						regulator-off-in-suspend;
					};
				};

				SWITCH_REG2 {
					regulator-boot-on;
					regulator-always-on;
					regulator-name = "vcc3v3_s0";
					phandle = <0xfb>;

					regulator-state-mem {
						regulator-off-in-suspend;
					};
				};

				LDO_REG8 {
					regulator-max-microvolt = <0x2dc6c0>;
					regulator-boot-on;
					regulator-always-on;
					regulator-min-microvolt = <0x2dc6c0>;
					regulator-name = "vcc_3v0";
					phandle = <0xfa>;

					regulator-state-mem {
						regulator-suspend-microvolt = <0x2dc6c0>;
						regulator-on-in-suspend;
					};
				};

				LDO_REG6 {
					regulator-max-microvolt = <0x16e360>;
					regulator-boot-on;
					regulator-always-on;
					regulator-min-microvolt = <0x16e360>;
					regulator-name = "vcc_1v5";
					phandle = <0xf8>;

					regulator-state-mem {
						regulator-suspend-microvolt = <0x16e360>;
						regulator-on-in-suspend;
					};
				};
			};
		};

		vdd_cpu_b@60 {
			regulator-max-microvolt = <0x1312d0>;
			pinctrl-names = "default";
			regulator-boot-on;
			pinctrl-0 = <0x7e>;
			regulator-initial-state = <0x03>;
			regulator-always-on;
			regulator-min-microvolt = "", "\f5";
			regulator-name = "vdd_cpu_b";
			regulator-ramp-delay = <0x3e8>;
			fcs,suspend-voltage-selector = <0x01>;
			compatible = "fcs,fan53200";
			status = "okay";
			reg = <0x60>;
			phandle = <0x10>;
			vsel-gpios = <0x79 0x11 0x00>;
			vin-supply = <0x7d>;
			regulator-compatible = "fan53555-regulator";

			regulator-state-mem {
				regulator-off-in-suspend;
			};
		};
	};

	qos@ffab0000 {
		compatible = "rockchip,rk3399-qos", "syscon";
		reg = <0x00 0xffab0000 0x00 0x20>;
		phandle = <0x5e>;
	};

	hdmi@ff940000 {
		power-domains = <0x1e 0x15>;
		reg-io-width = <0x04>;
		clock-names = "iahb", "isfr", "cec", "grf", "ref";
		interrupts = <0x00 0x17 0x04 0x00>;
		clocks = <0x08 0x174 0x08 0x71 0x08 0x70 0x08 0x16f 0x08 0x07>;
		ddc-i2c-bus = <0xaa>;
		#sound-dai-cells = <0x00>;
		compatible = "rockchip,rk3399-dw-hdmi";
		status = "okay";
		rockchip,grf = <0x1f>;
		reg = <0x00 0xff940000 0x00 0x20000>;
		phandle = <0xa9>;

		ports {
			#address-cells = <0x01>;
			#size-cells = <0x00>;

			port@0 {
				#address-cells = <0x01>;
				#size-cells = <0x00>;
				reg = <0x00>;
				phandle = <0x11c>;

				endpoint@1 {
					remote-endpoint = <0xac>;
					reg = <0x01>;
					phandle = <0x9b>;
				};

				endpoint@0 {
					remote-endpoint = <0xab>;
					reg = <0x00>;
					phandle = <0xa1>;
				};
			};

			port@1 {
				reg = <0x01>;
				phandle = <0x11d>;
			};
		};
	};

	phy@ff800000 {
		power-domains = <0x1e 0x09>;
		clock-names = "tcpdcore", "tcpdphy-ref";
		assigned-clocks = <0x08 0x80>;
		assigned-clock-rates = <0x2faf080>;
		resets = <0x08 0x9d 0x08 0x9c 0x08 0x14d>;
		clocks = <0x08 0x80 0x08 0x7f>;
		compatible = "rockchip,rk3399-typec-phy";
		status = "okay";
		rockchip,grf = <0x1f>;
		reg = <0x00 0xff800000 0x00 0x40000>;
		phandle = <0x111>;
		reset-names = "uphy", "uphy-pipe", "uphy-tcphy";

		dp-port {
			#phy-cells = <0x00>;
			phandle = <0x112>;
		};

		usb3-port {
			#phy-cells = <0x00>;
			phandle = <0x32>;
		};
	};

	qos@ffaa8000 {
		compatible = "rockchip,rk3399-qos", "syscon";
		reg = <0x00 0xffaa8000 0x00 0x20>;
		phandle = <0x6d>;
	};

	clock-controller@ff750000 {
		#reset-cells = <0x01>;
		clock-names = "xin24m";
		assigned-clocks = <0x72 0x01>;
		assigned-clock-rates = <0x284af100>;
		clocks = <0x8e>;
		#clock-cells = <0x01>;
		compatible = "rockchip,rk3399-pmucru";
		rockchip,grf = <0x13>;
		reg = <0x00 0xff750000 0x00 0x1000>;
		phandle = <0x72>;
	};

	crypto@ff8b8000 {
		clock-names = "hclk_master", "hclk_slave", "sclk";
		resets = <0x08 0xba 0x08 0xb8 0x08 0xb9>;
		interrupts = <0x00 0x87 0x04 0x00>;
		clocks = <0x08 0x1d1 0x08 0x1d3 0x08 0x86>;
		compatible = "rockchip,rk3399-crypto";
		reg = <0x00 0xff8b8000 0x00 0x4000>;
		phandle = <0xd4>;
		reset-names = "master", "slave", "crypto-rst";
	};

	aliases {
		i2c3 = "/i2c@ff130000";
		spi2 = "/spi@ff1e0000";
		gpio0 = "/pinctrl/gpio@ff720000";
		i2c1 = "/i2c@ff110000";
		spi0 = "/spi@ff1c0000";
		i2c8 = "/i2c@ff3e0000";
		serial3 = "/serial@ff1b0000";
		i2c6 = "/i2c@ff150000";
		serial1 = "/serial@ff190000";
		spi5 = "/spi@ff200000";
		gpio3 = "/pinctrl/gpio@ff788000";
		i2c4 = "/i2c@ff3d0000";
		spi3 = "/spi@ff350000";
		gpio1 = "/pinctrl/gpio@ff730000";
		i2c2 = "/i2c@ff120000";
		spi1 = "/spi@ff1d0000";
		i2c0 = "/i2c@ff3c0000";
		serial4 = "/serial@ff370000";
		i2c7 = "/i2c@ff160000";
		serial2 = "/serial@ff1a0000";
		gpio4 = "/pinctrl/gpio@ff790000";
		i2c5 = "/i2c@ff140000";
		serial0 = "/serial@ff180000";
		spi4 = "/spi@ff1f0000";
		gpio2 = "/pinctrl/gpio@ff780000";
	};

	qos@ffac0080 {
		compatible = "rockchip,rk3399-qos", "syscon";
		reg = <0x00 0xffac0080 0x00 0x20>;
		phandle = <0x62>;
	};

	usb@fe800000 {
		#address-cells = <0x02>;
		clock-names = "ref_clk", "suspend_clk", "bus_clk", "aclk_usb3_rksoc_axi_perf", "aclk_usb3", "grf_clk";
		resets = <0x08 0x125>;
		clocks = <0x08 0x81 0x08 0x83 0x08 0xf6 0x08 0xf8 0x08 0xf4 0x08 0xf9>;
		#size-cells = <0x02>;
		compatible = "rockchip,rk3399-dwc3";
		ranges;
		status = "okay";
		phandle = <0xcc>;
		reset-names = "usb3-otg";

		usb@fe800000 {
			power-domains = <0x1e 0x18>;
			snps,dis_enblslpm_quirk;
			phy-names = "usb2-phy", "usb3-phy";
			clock-names = "ref", "bus_early", "suspend";
			snps,dis-u2-freeclk-exists-quirk;
			phy_type = "utmi_wide";
			snps,dis_u2_susphy_quirk;
			interrupts = <0x00 0x69 0x04 0x00>;
			clocks = <0x08 0x81 0x08 0xf6 0x08 0x83>;
			extcon = <0x30>;
			snps,usb3-phy-reset-quirk;
			compatible = "snps,dwc3";
			snps,dis-del-phy-power-chg-quirk;
			status = "okay";
			snps,xhci-trb-ent-quirk;
			phys = <0x2e 0x2f>;
			reg = <0x00 0xfe800000 0x00 0x100000>;
			phandle = <0xcd>;
			dr_mode = "otg";
			snps,dis-tx-ipgap-linecheck-quirk;
		};
	};

	memory-controller {
		clock-names = "dmc_clk";
		clocks = <0x08 0xa8>;
		devfreq-events = <0x14>;
		compatible = "rockchip,rk3399-dmc";
		rockchip,pmu = <0x13>;
		status = "disabled";
		phandle = <0xc2>;
		operating-points-v2 = <0x15>;
	};

	qos@ffa60180 {
		compatible = "rockchip,rk3399-qos", "syscon";
		reg = <0x00 0xffa60180 0x00 0x20>;
		phandle = <0xea>;
	};

	usb@fe3c0000 {
		phy-names = "usb";
		interrupts = <0x00 0x1e 0x04 0x00>;
		clocks = <0x08 0x1ca 0x08 0x1cb 0x2c>;
		compatible = "generic-ehci";
		status = "okay";
		phys = <0x2d>;
		reg = <0x00 0xfe3c0000 0x00 0x20000>;
		phandle = <0xca>;
	};

	dsi@ff968000 {
		power-domains = <0x1e 0x0f>;
		clock-names = "ref", "pclk", "phy_cfg", "grf";
		resets = <0x08 0xfc>;
		interrupts = <0x00 0x2e 0x04 0x00>;
		clocks = <0x08 0xa2 0x08 0x171 0x08 0xa4 0x08 0x16f>;
		#phy-cells = <0x00>;
		compatible = "rockchip,rk3399-mipi-dsi", "snps,dw-mipi-dsi";
		status = "disabled";
		rockchip,grf = <0x1f>;
		reg = <0x00 0xff968000 0x00 0x8000>;
		phandle = <0xa7>;
		reset-names = "apb";

		ports {
			#address-cells = <0x01>;
			#size-cells = <0x00>;

			port@0 {
				#address-cells = <0x01>;
				#size-cells = <0x00>;
				reg = <0x00>;
				phandle = <0x121>;

				endpoint@1 {
					remote-endpoint = <0xb0>;
					reg = <0x01>;
					phandle = <0x9c>;
				};

				endpoint@0 {
					remote-endpoint = <0xaf>;
					reg = <0x00>;
					phandle = <0xa2>;
				};
			};

			port@1 {
				reg = <0x01>;
				phandle = <0x122>;
			};
		};
	};

	i2s@ff8a0000 {
		power-domains = <0x1e 0x1c>;
		clock-names = "i2s_clk", "i2s_hclk";
		interrupts = <0x00 0x29 0x04 0x00>;
		clocks = <0x08 0x58 0x08 0x1d6>;
		dma-names = "tx", "rx";
		#sound-dai-cells = <0x00>;
		compatible = "rockchip,rk3399-i2s", "rockchip,rk3066-i2s";
		status = "okay";
		reg = <0x00 0xff8a0000 0x00 0x1000>;
		phandle = <0xa8>;
		dmas = <0x51 0x04 0x51 0x05>;
	};

	i2c@ff140000 {
		pinctrl-names = "default";
		#address-cells = <0x01>;
		pinctrl-0 = <0x39>;
		clock-names = "i2c", "pclk";
		assigned-clocks = <0x08 0x44>;
		assigned-clock-rates = <0xbebc200>;
		interrupts = <0x00 0x26 0x04 0x00>;
		clocks = <0x08 0x44 0x08 0x158>;
		#size-cells = <0x00>;
		compatible = "rockchip,rk3399-i2c";
		status = "disabled";
		reg = <0x00 0xff140000 0x00 0x1000>;
		phandle = <0xd7>;
	};

	typec-extcon {
		svid = [ff 01];
		orientation-switch;
		usb-role-switch;
		compatible = "linux,typec-extcon-bridge";
		mode-switch;
		phandle = <0x30>;
	};

	chosen {
		u-boot,version = "2025.04_armbian-2025.04-S3482-Pb4d9-Hadda-V681f-B6a81-R448a-dirty";
		linux,initrd-end = <0x00 0xf0ec59e7>;
		bootargs = "root=UUID=e82d2a44-4777-4f42-8ebe-41afd3a71bf4 rootwait rootfstype=ext4 splash=verbose console=ttyS2,1500000 console=tty1 consoleblank=0 loglevel=1 ubootpart=b73d4037-01 usb-storage.quirks=0x2537:0x1066:u,0x2537:0x1068:u   cgroup_enable=cpuset cgroup_memory=1 cgroup_enable=memory";
		kaslr-seed = <0x00 0x00>;
		linux,initrd-start = <0x00 0xef5ed000>;
		stdout-path = "serial2:1500000n8";
	};

	vop@ff900000 {
		power-domains = <0x1e 0x11>;
		iommus = <0x9e>;
		clock-names = "aclk_vop", "dclk_vop", "hclk_vop";
		assigned-clocks = <0x08 0xd9 0x08 0x1d9>;
		assigned-clock-rates = <0x17d78400 0x5f5e100>;
		resets = <0x08 0x112 0x08 0x116 0x08 0x118>;
		interrupts = <0x00 0x76 0x04 0x00>;
		clocks = <0x08 0xd9 0x08 0xb4 0x08 0x1d9>;
		compatible = "rockchip,rk3399-vop-big";
		status = "okay";
		reg = <0x00 0xff900000 0x00 0x2000 0x00 0xff902000 0x00 0x1000>;
		phandle = <0x118>;
		reset-names = "axi", "ahb", "dclk";

		port {
			#address-cells = <0x01>;
			#size-cells = <0x00>;
			phandle = <0x12>;

			endpoint@3 {
				remote-endpoint = <0xa2>;
				reg = <0x03>;
				phandle = <0xaf>;
			};

			endpoint@1 {
				remote-endpoint = <0xa0>;
				reg = <0x01>;
				phandle = <0xad>;
			};

			endpoint@4 {
				remote-endpoint = <0xa3>;
				reg = <0x04>;
				phandle = <0x34>;
			};

			endpoint@2 {
				remote-endpoint = <0xa1>;
				reg = <0x02>;
				phandle = <0xab>;
			};

			endpoint@0 {
				remote-endpoint = <0x9f>;
				reg = <0x00>;
				phandle = <0xb2>;
			};
		};
	};

	serial@ff190000 {
		reg-io-width = <0x04>;
		pinctrl-names = "default";
		pinctrl-0 = <0x3d>;
		clock-names = "baudclk", "apb_pclk";
		interrupts = <0x00 0x62 0x04 0x00>;
		clocks = <0x08 0x52 0x08 0x161>;
		compatible = "rockchip,rk3399-uart", "snps,dw-apb-uart";
		status = "disabled";
		reg = <0x00 0xff190000 0x00 0x100>;
		phandle = <0xdb>;
		reg-shift = <0x02>;
	};

	iommu@ff650800 {
		power-domains = <0x1e 0x1f>;
		clock-names = "aclk", "iface";
		interrupts = <0x00 0x73 0x04 0x00>;
		clocks = <0x08 0xeb 0x08 0x1ea>;
		#iommu-cells = <0x00>;
		compatible = "rockchip,iommu";
		reg = <0x00 0xff650800 0x00 0x40>;
		phandle = <0x8b>;
	};

	qos@ffa5c000 {
		compatible = "rockchip,rk3399-qos", "syscon";
		reg = <0x00 0xffa5c000 0x00 0x20>;
		phandle = <0x65>;
	};

	spi@ff1c0000 {
		pinctrl-names = "default";
		#address-cells = <0x01>;
		pinctrl-0 = <0x41 0x42 0x43 0x44>;
		clock-names = "spiclk", "apb_pclk";
		interrupts = <0x00 0x44 0x04 0x00>;
		clocks = <0x08 0x47 0x08 0x15b>;
		#size-cells = <0x00>;
		dma-names = "tx", "rx";
		compatible = "rockchip,rk3399-spi", "rockchip,rk3066-spi";
		status = "disabled";
		reg = <0x00 0xff1c0000 0x00 0x1000>;
		phandle = <0xde>;
		dmas = <0x40 0x0a 0x40 0x0b>;
	};

	dma-controller@ff6d0000 {
		clock-names = "apb_pclk";
		interrupts = <0x00 0x05 0x04 0x00 0x00 0x06 0x04 0x00>;
		clocks = <0x08 0xd3>;
		arm,pl330-periph-burst;
		compatible = "arm,pl330", "arm,primecell";
		reg = <0x00 0xff6d0000 0x00 0x4000>;
		phandle = <0x51>;
		#dma-cells = <0x01>;
	};

	pcie-ep@f8000000 {
		pinctrl-names = "default";
		phy-names = "pcie-phy-0", "pcie-phy-1", "pcie-phy-2", "pcie-phy-3";
		pinctrl-0 = <0x1d>;
		clock-names = "aclk", "aclk-perf", "hclk", "pm";
		reg-names = "apb-base", "mem-base";
		resets = <0x08 0x82 0x08 0x83 0x08 0x84 0x08 0x85 0x08 0x86 0x08 0x81 0x08 0x80>;
		clocks = <0x08 0xc5 0x08 0xc4 0x08 0x147 0x08 0xa0>;
		max-functions = [08];
		num-lanes = <0x04>;
		compatible = "rockchip,rk3399-pcie-ep";
		status = "disabled";
		phys = <0x1a 0x00 0x1a 0x01 0x1a 0x02 0x1a 0x03>;
		rockchip,max-outbound-regions = <0x20>;
		reg = <0x00 0xfd000000 0x00 0x1000000 0x00 0xfa000000 0x00 0x2000000>;
		phandle = <0xc4>;
		reset-names = "core", "mgmt", "mgmt-sticky", "pipe", "pm", "pclk", "aclk";
	};

	external-gmac-clock {
		clock-output-names = "clkin_gmac";
		#clock-cells = <0x00>;
		clock-frequency = <0x7735940>;
		compatible = "fixed-clock";
		phandle = <0x160>;
	};

	pmu_a53 {
		interrupts = <0x01 0x07 0x08 0x16>;
		compatible = "arm,cortex-a53-pmu";
	};

	isp0@ff910000 {
		power-domains = <0x1e 0x13>;
		iommus = <0xa4>;
		phy-names = "dphy";
		clock-names = "isp", "aclk", "hclk";
		interrupts = <0x00 0x2b 0x04 0x00>;
		clocks = <0x08 0x6e 0x08 0xe9 0x08 0x1e3>;
		compatible = "rockchip,rk3399-cif-isp";
		status = "disabled";
		phys = <0xa5>;
		reg = <0x00 0xff910000 0x00 0x4000>;
		phandle = <0x119>;

		ports {
			#address-cells = <0x01>;
			#size-cells = <0x00>;

			port@0 {
				#address-cells = <0x01>;
				#size-cells = <0x00>;
				reg = <0x00>;
			};
		};
	};

	vbus-5vout {
		regulator-max-microvolt = <0x4c4b40>;
		pinctrl-names = "default";
		gpio = <0x79 0x03 0x00>;
		pinctrl-0 = <0xc0>;
		enable-active-high;
		regulator-min-microvolt = <0x4c4b40>;
		regulator-name = "vbus_5vout";
		compatible = "regulator-fixed";
		phandle = <0x81>;
		vin-supply = <0x7d>;

		regulator-state-mem {
			regulator-off-in-suspend;
		};
	};

	debug@fe436000 {
		clock-names = "apb_pclk";
		clocks = <0x08 0x14d>;
		cpu = <0x05>;
		compatible = "arm,coresight-cpu-debug", "arm,primecell";
		reg = <0x00 0xfe436000 0x00 0x1000>;
	};

	cpus {
		#address-cells = <0x02>;
		#size-cells = <0x00>;

		cpu@1 {
			d-cache-line-size = <0x40>;
			capacity-dmips-mhz = <0x1e5>;
			cpu-supply = <0x0d>;
			clocks = <0x08 0x08>;
			i-cache-line-size = <0x40>;
			cpu-idle-states = <0x09 0x0a>;
			device_type = "cpu";
			compatible = "arm,cortex-a53";
			dynamic-power-coefficient = <0x64>;
			d-cache-size = <0x8000>;
			next-level-cache = <0x0b>;
			i-cache-size = <0x8000>;
			reg = <0x00 0x01>;
			enable-method = "psci";
			phandle = <0x03>;
			d-cache-sets = <0x80>;
			operating-points-v2 = <0x0c>;
			i-cache-sets = <0x100>;
			#cooling-cells = <0x02>;
		};

		cpu@101 {
			d-cache-line-size = <0x40>;
			capacity-dmips-mhz = <0x400>;
			cpu-supply = <0x10>;
			clocks = <0x08 0x09>;
			i-cache-line-size = <0x40>;
			cpu-idle-states = <0x09 0x0a>;
			device_type = "cpu";
			compatible = "arm,cortex-a72";
			dynamic-power-coefficient = <0x1b4>;
			d-cache-size = <0x8000>;
			next-level-cache = <0x0e>;
			i-cache-size = <0xc000>;
			reg = <0x00 0x101>;
			enable-method = "psci";
			phandle = <0x07>;
			d-cache-sets = <0x100>;
			operating-points-v2 = <0x0f>;
			i-cache-sets = <0x100>;
			#cooling-cells = <0x02>;

			thermal-idle {
				exit-latency-us = <0x1f4>;
				duration-us = <0x2710>;
				#cooling-cells = <0x02>;
			};
		};

		idle-states {
			entry-method = "psci";

			cluster-sleep {
				entry-latency-us = <0x190>;
				local-timer-stop;
				exit-latency-us = <0x1f4>;
				arm,psci-suspend-param = <0x1010000>;
				compatible = "arm,idle-state";
				phandle = <0x0a>;
				min-residency-us = <0x7d0>;
			};

			cpu-sleep {
				entry-latency-us = <0x78>;
				local-timer-stop;
				exit-latency-us = <0xfa>;
				arm,psci-suspend-param = <0x10000>;
				compatible = "arm,idle-state";
				phandle = <0x09>;
				min-residency-us = <0x384>;
			};
		};

		l2-cache-cluster1 {
			cache-size = <0x100000>;
			cache-level = <0x02>;
			cache-sets = <0x400>;
			cache-unified;
			compatible = "cache";
			cache-line-size = <0x40>;
			phandle = <0x0e>;
		};

		cpu-map {

			cluster0 {

				core3 {
					cpu = <0x05>;
				};

				core1 {
					cpu = <0x03>;
				};

				core2 {
					cpu = <0x04>;
				};

				core0 {
					cpu = <0x02>;
				};
			};

			cluster1 {

				core1 {
					cpu = <0x07>;
				};

				core0 {
					cpu = <0x06>;
				};
			};
		};

		cpu@2 {
			d-cache-line-size = <0x40>;
			capacity-dmips-mhz = <0x1e5>;
			cpu-supply = <0x0d>;
			clocks = <0x08 0x08>;
			i-cache-line-size = <0x40>;
			cpu-idle-states = <0x09 0x0a>;
			device_type = "cpu";
			compatible = "arm,cortex-a53";
			dynamic-power-coefficient = <0x64>;
			d-cache-size = <0x8000>;
			next-level-cache = <0x0b>;
			i-cache-size = <0x8000>;
			reg = <0x00 0x02>;
			enable-method = "psci";
			phandle = <0x04>;
			d-cache-sets = <0x80>;
			operating-points-v2 = <0x0c>;
			i-cache-sets = <0x100>;
			#cooling-cells = <0x02>;
		};

		cpu@0 {
			d-cache-line-size = <0x40>;
			capacity-dmips-mhz = <0x1e5>;
			cpu-supply = <0x0d>;
			clocks = <0x08 0x08>;
			i-cache-line-size = <0x40>;
			cpu-idle-states = <0x09 0x0a>;
			device_type = "cpu";
			compatible = "arm,cortex-a53";
			dynamic-power-coefficient = <0x64>;
			d-cache-size = <0x8000>;
			next-level-cache = <0x0b>;
			i-cache-size = <0x8000>;
			reg = <0x00 0x00>;
			enable-method = "psci";
			phandle = <0x02>;
			d-cache-sets = <0x80>;
			operating-points-v2 = <0x0c>;
			i-cache-sets = <0x100>;
			#cooling-cells = <0x02>;
		};

		cpu@100 {
			d-cache-line-size = <0x40>;
			capacity-dmips-mhz = <0x400>;
			cpu-supply = <0x10>;
			clocks = <0x08 0x09>;
			i-cache-line-size = <0x40>;
			cpu-idle-states = <0x09 0x0a>;
			device_type = "cpu";
			compatible = "arm,cortex-a72";
			dynamic-power-coefficient = <0x1b4>;
			d-cache-size = <0x8000>;
			next-level-cache = <0x0e>;
			i-cache-size = <0xc000>;
			reg = <0x00 0x100>;
			enable-method = "psci";
			phandle = <0x06>;
			d-cache-sets = <0x100>;
			operating-points-v2 = <0x0f>;
			i-cache-sets = <0x100>;
			#cooling-cells = <0x02>;

			thermal-idle {
				exit-latency-us = <0x1f4>;
				duration-us = <0x2710>;
				#cooling-cells = <0x02>;
			};
		};

		cpu@3 {
			d-cache-line-size = <0x40>;
			capacity-dmips-mhz = <0x1e5>;
			cpu-supply = <0x0d>;
			clocks = <0x08 0x08>;
			i-cache-line-size = <0x40>;
			cpu-idle-states = <0x09 0x0a>;
			device_type = "cpu";
			compatible = "arm,cortex-a53";
			dynamic-power-coefficient = <0x64>;
			d-cache-size = <0x8000>;
			next-level-cache = <0x0b>;
			i-cache-size = <0x8000>;
			reg = <0x00 0x03>;
			enable-method = "psci";
			phandle = <0x05>;
			d-cache-sets = <0x80>;
			operating-points-v2 = <0x0c>;
			i-cache-sets = <0x100>;
			#cooling-cells = <0x02>;
		};

		l2-cache-cluster0 {
			cache-size = <0x80000>;
			cache-level = <0x02>;
			cache-sets = <0x200>;
			cache-unified;
			compatible = "cache";
			cache-line-size = <0x40>;
			phandle = <0x0b>;
		};
	};

	__symbols__ {
		i2s0_2ch_bus = "/pinctrl/i2s0/i2s0-2ch-bus";
		i2c3 = "/i2c@ff130000";
		usb_host1_ohci = "/usb@fe3e0000";
		spi5_clk = "/pinctrl/spi5/spi5-clk";
		vcc3v3_s3 = "/i2c@ff3c0000/pmic@1b/regulators/SWITCH_REG1";
		sdmmc_clk = "/pinctrl/sdmmc/sdmmc-clk";
		vcc5v0_typec0_en_pin = "/pinctrl/usb-typec/vcc5v0-typec0-en-pin";
		vopl_out_mipi = "/vop@ff8f0000/port/endpoint@0";
		tcphy1 = "/phy@ff800000";
		cpu_crit = "/thermal-zones/cpu-thermal/trips/cpu_crit";
		thermal_zones = "/thermal-zones";
		qos_gpu = "/qos@ffae0000";
		qos_iep = "/qos@ffa98000";
		clk_32k = "/pinctrl/clock/clk-32k";
		cpu_l1 = "/cpus/cpu@1";
		vcc3v3_csi = "/i2c@ff3c0000/pmic@1b/regulators/LDO_REG5";
		spi2 = "/spi@ff1e0000";
		pcfg_pull_down_12ma = "/pinctrl/pcfg-pull-down-12ma";
		qos_isp0_m0 = "/qos@ffaa0000";
		gpio0 = "/pinctrl/gpio@ff720000";
		spi4_tx = "/pinctrl/spi4/spi4-tx";
		saradc = "/saradc@ff100000";
		test_clkout1 = "/pinctrl/testclk/test-clkout1";
		vop0_pwm_pin = "/pinctrl/pwm0/vop0-pwm-pin";
		cluster1_opp = "/opp-table-1";
		mipi1_in_vopl = "/dsi@ff968000/ports/port@0/endpoint@1";
		spi0_cs0 = "/pinctrl/spi0/spi0-cs0";
		dfi = "/dfi@ff630000";
		pinctrl = "/pinctrl";
		cif_clkin = "/pinctrl/cif/cif-clkin";
		qos_rga_r = "/qos@ffab0000";
		spi1_tx = "/pinctrl/spi1/spi1-tx";
		dmac_peri = "/dma-controller@ff6e0000";
		vdd_cpu_b = "/i2c@ff3c0000/vdd_cpu_b@60";
		i2s1 = "/i2s@ff890000";
		hdmi_cec = "/pinctrl/hdmi/hdmi-cec";
		i2c1 = "/i2c@ff110000";
		gpu_leakage = "/efuse@ff690000/gpu-leakage@18";
		gmac = "/ethernet@fe300000";
		qos_usb_otg1 = "/qos@ffa70080";
		spi4_cs0 = "/pinctrl/spi4/spi4-cs0";
		pwm3a_pin = "/pinctrl/pwm3a/pwm3a-pin";
		spi4_rx = "/pinctrl/spi4/spi4-rx";
		i2c4_xfer = "/pinctrl/i2c4/i2c4-xfer";
		pcfg_pull_none = "/pinctrl/pcfg-pull-none";
		tcphy1_usb3 = "/phy@ff800000/usb3-port";
		otp_out = "/pinctrl/tsadc/otp-out";
		vopl_out_dp = "/vop@ff8f0000/port/endpoint@4";
		vopl_mmu = "/iommu@ff8f3f00";
		gpu_alert0 = "/thermal-zones/gpu-thermal/trips/gpu_alert0";
		CLUSTER_SLEEP = "/cpus/idle-states/cluster-sleep";
		spi1_rx = "/pinctrl/spi1/spi1-rx";
		sdhci = "/mmc@fe330000";
		sdmmc_bus1 = "/pinctrl/sdmmc/sdmmc-bus1";
		u2phy1 = "/syscon@ff770000/usb2phy@e460";
		gpu = "/gpu@ff9a0000";
		spi0 = "/spi@ff1c0000";
		iep = "/iep@ff670000";
		isp0 = "/isp0@ff910000";
		pwm0_pin = "/pinctrl/pwm0/pwm0-pin";
		clkin_gmac = "/external-gmac-clock";
		vsel2_gpio = "/pinctrl/pmic/vsel2-gpio";
		usb_host0_ohci = "/usb@fe3a0000";
		dp_in_vopl = "/dp@fec00000/ports/port/endpoint@1";
		sdio0_cmd = "/pinctrl/sdio0/sdio0-cmd";
		dmc = "/memory-controller";
		usbc_hs = "/i2c@ff3d0000/fusb30x@22/connector/ports/port@0/endpoint";
		qos_isp1_m1 = "/qos@ffaa8080";
		qos_emmc = "/qos@ffa58000";
		edp_in = "/dp@ff970000/ports/port@0";
		mipi_dphy_rx0 = "/syscon@ff770000/mipi-dphy-rx0";
		uart3_cts = "/pinctrl/uart3/uart3-cts";
		vcc1v8_pmu = "/i2c@ff3c0000/pmic@1b/regulators/LDO_REG3";
		rmii_pins = "/pinctrl/gmac/rmii-pins";
		pmugrf = "/syscon@ff320000";
		tcphy0_typec_dp = "/phy@ff7c0000/dp-port/port/endpoint";
		gpio_fan_pin = "/pinctrl/fan/gpio-fan-pin";
		sdmmc_wp = "/pinctrl/sdmmc/sdmmc-wp";
		logic_leakage = "/efuse@ff690000/logic-leakage@1b";
		fusb0_int = "/pinctrl/fusb30x/fusb0-int";
		sdio0_bkpwr = "/pinctrl/sdio0/sdio0-bkpwr";
		rktimer = "/rktimer@ff850000";
		vopl = "/vop@ff8f0000";
		qos_pcie = "/qos@ffa60080";
		fusb0 = "/i2c@ff3d0000/fusb30x@22";
		crypto1 = "/crypto@ff8b8000";
		spi2_clk = "/pinctrl/spi2/spi2-clk";
		i2s0_8ch_bus_bclk_off = "/pinctrl/i2s0/i2s0-8ch-bus-bclk-off";
		dmc_opp_table = "/opp-table-3";
		gpu_crit = "/thermal-zones/gpu-thermal/trips/gpu_crit";
		vdd_center = "/i2c@ff3c0000/pmic@1b/regulators/DCDC_REG1";
		pcfg_pull_down_18ma = "/pinctrl/pcfg-pull-down-18ma";
		uart4 = "/serial@ff370000";
		uarthdcp_xfer = "/pinctrl/uarthdcp/uarthdcp-xfer";
		u2phy1_host = "/syscon@ff770000/usb2phy@e460/host-port";
		pcie_clkreqnb_cpm = "/pinctrl/pcie/pci-clkreqnb-cpm";
		vdd_gpu = "/i2c@ff3d0000/vdd_gpu@60";
		xin32k = "/xin32k";
		i2c8 = "/i2c@ff3e0000";
		cpu_alert0 = "/thermal-zones/cpu-thermal/trips/cpu_alert0";
		i2c3_xfer = "/pinctrl/i2c3/i2c3-xfer";
		cpu_thermal = "/thermal-zones/cpu-thermal";
		tcphy0_usb3 = "/phy@ff7c0000/usb3-port";
		power = "/power-management@ff310000/power-controller";
		edp_in_vopl = "/dp@ff970000/ports/port@0/endpoint@1";
		mipi_in = "/dsi@ff960000/ports/port@0";
		vopl_out = "/vop@ff8f0000/port";
		l2_cache_b = "/cpus/l2-cache-cluster1";
		pwm3 = "/pwm@ff420030";
		tcphy1_dp = "/phy@ff800000/dp-port";
		vbus_typec = "/vbus-5vout";
		vdec_mmu = "/iommu@ff660480";
		usbc_ss = "/i2c@ff3d0000/fusb30x@22/connector/ports/port@1/endpoint";
		sdio0_bus4 = "/pinctrl/sdio0/sdio0-bus4";
		edp_hpd = "/pinctrl/edp/edp-hpd";
		vcc5v0_host = "/vcc5v0-host-regulator";
		cru = "/clock-controller@ff760000";
		vsel1_gpio = "/pinctrl/pmic/vsel1-gpio";
		cpu_b1 = "/cpus/cpu@101";
		uart4_xfer = "/pinctrl/uart4/uart4-xfer";
		mipi_dsi1 = "/dsi@ff968000";
		pcfg_pull_down_20ma = "/pinctrl/pcfg-pull-down-20ma";
		uart2 = "/serial@ff1a0000";
		spi1_cs0 = "/pinctrl/spi1/spi1-cs0";
		qos_usb_host0 = "/qos@ffa60100";
		typec_extcon_bridge = "/typec-extcon";
		qos_rga_w = "/qos@ffab0080";
		pcfg_output_low = "/pinctrl/pcfg-output-low";
		ppi_cluster0 = "/interrupt-controller@fee00000/ppi-partitions/interrupt-partition-0";
		i2c6 = "/i2c@ff150000";
		vdec = "/video-codec@ff660000";
		sdio0_clk = "/pinctrl/sdio0/sdio0-clk";
		pmu_io_domains = "/syscon@ff320000/io-domains";
		pcfg_pull_none_13ma = "/pinctrl/pcfg-pull-none-13ma";
		spi5_cs0 = "/pinctrl/spi5/spi5-cs0";
		hdmi_i2c_xfer = "/pinctrl/hdmi/hdmi-i2c-xfer";
		gic = "/interrupt-controller@fee00000";
		pcfg_input_pull_down = "/pinctrl/pcfg-input-pull-down";
		hdmi_in_vopb = "/hdmi@ff940000/ports/port@0/endpoint@0";
		pcie0 = "/pcie@f8000000";
		pwm3b_pin = "/pinctrl/pwm3b/pwm3b-pin";
		pcfg_pull_down_8ma = "/pinctrl/pcfg-pull-down-8ma";
		efuse0 = "/efuse@ff690000";
		usbdrd3_1 = "/usb@fe900000";
		pwm1 = "/pwm@ff420010";
		cpu_id = "/efuse@ff690000/cpu-id@7";
		vpu = "/video-codec@ff650000";
		edp = "/dp@ff970000";
		usbdrd_dwc3_0 = "/usb@fe800000/usb@fe800000";
		otp_pin = "/pinctrl/tsadc/otp-pin";
		u2phy0_host = "/syscon@ff770000/usb2phy@e450/host-port";
		i2s0_2ch_bus_bclk_off = "/pinctrl/i2s0/i2s0-2ch-bus-bclk-off";
		spi3_tx = "/pinctrl/spi3/spi3-tx";
		usb_host1_ehci = "/usb@fe3c0000";
		xin24m = "/xin24m";
		pcfg_pull_up_2ma = "/pinctrl/pcfg-pull-up-2ma";
		spi5 = "/spi@ff200000";
		tsadc = "/tsadc@ff260000";
		uart0_cts = "/pinctrl/uart0/uart0-cts";
		gpio3 = "/pinctrl/gpio@ff788000";
		pwm1_pin = "/pinctrl/pwm1/pwm1-pin";
		gpu_opp_table = "/opp-table-2";
		pcfg_output_high = "/pinctrl/pcfg-output-high";
		spi0_tx = "/pinctrl/spi0/spi0-tx";
		uart0 = "/serial@ff180000";
		pwm1_pin_pull_down = "/pinctrl/pwm1/pwm1-pin-pull-down";
		ddrio_pwroff = "/pinctrl/suspend/ddrio-pwroff";
		uart3_rts = "/pinctrl/uart3/uart3-rts";
		i2c2_xfer = "/pinctrl/i2c2/i2c2-xfer";
		pmic_int_l = "/pinctrl/pmic/pmic-int-l";
		pcie_phy = "/syscon@ff770000/pcie-phy";
		rk808 = "/i2c@ff3c0000/pmic@1b";
		vcc5v0_host_en = "/pinctrl/usb2/vcc5v0-host-en";
		board_info = "/board-info";
		u2phy0_otg = "/syscon@ff770000/usb2phy@e450/otg-port";
		qos_hdcp = "/qos@ffa90000";
		i2c4 = "/i2c@ff3d0000";
		cpul_leakage = "/efuse@ff690000/cpu-leakage@1a";
		spi3_rx = "/pinctrl/spi3/spi3-rx";
		vcc_1v5 = "/i2c@ff3c0000/pmic@1b/regulators/LDO_REG6";
		vcc_lcd = "/vcc-lcd";
		isp0_mmu = "/iommu@ff914000";
		spi0_rx = "/pinctrl/spi0/spi0-rx";
		mipi_in_vopl = "/dsi@ff960000/ports/port@0/endpoint@1";
		iep_mmu = "/iommu@ff670800";
		uart3_xfer = "/pinctrl/uart3/uart3-xfer";
		spdif = "/spdif@ff870000";
		vopl_out_edp = "/vop@ff8f0000/port/endpoint@1";
		spi3_clk = "/pinctrl/spi3/spi3-clk";
		i2c8_xfer = "/pinctrl/i2c8/i2c8-xfer";
		sdmmc_cd = "/pinctrl/sdmmc/sdmmc-cd";
		cpu_l2 = "/cpus/cpu@2";
		sdmmc_bus4 = "/pinctrl/sdmmc/sdmmc-bus4";
		sdio0_wp = "/pinctrl/sdio0/sdio0-wp";
		spi3 = "/spi@ff350000";
		qos_isp0_m1 = "/qos@ffaa0080";
		gpio1 = "/pinctrl/gpio@ff730000";
		test_clkout2 = "/pinctrl/testclk/test-clkout2";
		pcfg_pull_up_18ma = "/pinctrl/pcfg-pull-up-18ma";
		vcc5v0_sys = "/vcc5v0-sys";
		qos_vop_big_r = "/qos@ffac8000";
		spi0_cs1 = "/pinctrl/spi0/spi0-cs1";
		its = "/interrupt-controller@fee00000/msi-controller@fee20000";
		sdio0 = "/mmc@fe310000";
		hdmi_out = "/hdmi@ff940000/ports/port@1";
		i2s2 = "/i2s@ff8a0000";
		rgmii_pins = "/pinctrl/gmac/rgmii-pins";
		i2c2 = "/i2c@ff120000";
		spdif_bus = "/pinctrl/spdif/spdif-bus";
		vopb_mmu = "/iommu@ff903f00";
		mipi1_in_vopb = "/dsi@ff968000/ports/port@0/endpoint@0";
		pcie0_ep = "/pcie-ep@f8000000";
		sdmmc_pwr = "/pinctrl/sdio0/sdmmc-pwr";
		usb_host0_ehci = "/usb@fe380000";
		i2s1_2ch_bus = "/pinctrl/i2s1/i2s1-2ch-bus";
		vopb_out_mipi1 = "/vop@ff900000/port/endpoint@3";
		qos_vop_little = "/qos@ffad0000";
		tcphy0 = "/phy@ff7c0000";
		vopl_out_mipi1 = "/vop@ff8f0000/port/endpoint@3";
		tcphy0_typec_ss = "/phy@ff7c0000/usb3-port/port/endpoint";
		pcfg_pull_up_8ma = "/pinctrl/pcfg-pull-up-8ma";
		i2c1_xfer = "/pinctrl/i2c1/i2c1-xfer";
		vcca0v9_hdmi = "/i2c@ff3c0000/pmic@1b/regulators/LDO_REG7";
		vcc_3v0 = "/i2c@ff3c0000/pmic@1b/regulators/LDO_REG8";
		cpu_l0 = "/cpus/cpu@0";
		spi2_cs0 = "/pinctrl/spi2/spi2-cs0";
		pmucru = "/clock-controller@ff750000";
		vdd_log = "/vdd-log";
		pcfg_pull_down_4ma = "/pinctrl/pcfg-pull-down-4ma";
		vcc_ddr = "/i2c@ff3c0000/pmic@1b/regulators/DCDC_REG3";
		spi1 = "/spi@ff1d0000";
		vdd_cpu_l = "/i2c@ff3c0000/pmic@1b/regulators/DCDC_REG2";
		pcfg_pull_up_20ma = "/pinctrl/pcfg-pull-up-20ma";
		isp1 = "/isp1@ff920000";
		test_clkout0 = "/pinctrl/testclk/test-clkout0";
		vopb_out_dp = "/vop@ff900000/port/endpoint@4";
		vop1_pwm_pin = "/pinctrl/pwm0/vop1-pwm-pin";
		qos_video_m1_r = "/qos@ffac0000";
		tcphy0_dp = "/phy@ff7c0000/dp-port";
		sdmmc = "/mmc@fe320000";
		i2s0 = "/i2s@ff880000";
		spdif_bus_1 = "/pinctrl/spdif/spdif-bus-1";
		i2c0 = "/i2c@ff3c0000";
		dp_in_vopb = "/dp@fec00000/ports/port/endpoint@0";
		dmac_bus = "/dma-controller@ff6d0000";
		i2c7_xfer = "/pinctrl/i2c7/i2c7-xfer";
		vcc3v3_s0 = "/i2c@ff3c0000/pmic@1b/regulators/SWITCH_REG2";
		uart0_rts = "/pinctrl/uart0/uart0-rts";
		qos_usb_otg0 = "/qos@ffa70000";
		i2s0_8ch_bus = "/pinctrl/i2s0/i2s0-8ch-bus";
		pcfg_pull_none_12ma = "/pinctrl/pcfg-pull-none-12ma";
		uart2c_xfer = "/pinctrl/uart2c/uart2c-xfer";
		io_domains = "/syscon@ff770000/io-domains";
		m24c08 = "/i2c@ff3e0000/m24c08@50";
		pwm2_pin = "/pinctrl/pwm2/pwm2-pin";
		edp_out = "/dp@ff970000/ports/port@1";
		wafer_info = "/efuse@ff690000/wafer-info@1c";
		pcie0_intc = "/pcie@f8000000/interrupt-controller";
		cif_clkouta = "/pinctrl/cif/cif-clkouta";
		vopb = "/vop@ff900000";
		u2phy0 = "/syscon@ff770000/usb2phy@e450";
		vopb_out_hdmi = "/vop@ff900000/port/endpoint@2";
		u2phy1_otg = "/syscon@ff770000/usb2phy@e460/otg-port";
		vopb_out = "/vop@ff900000/port";
		qos_perihp = "/qos@ffad8080";
		spi0_clk = "/pinctrl/spi0/spi0-clk";
		cpu_alert1 = "/thermal-zones/cpu-thermal/trips/cpu_alert1";
		qos_isp1_m0 = "/qos@ffaa8000";
		spi5_tx = "/pinctrl/spi5/spi5-tx";
		isp1_mmu = "/iommu@ff924000";
		pcfg_input_pull_up = "/pinctrl/pcfg-input-pull-up";
		ap_pwroff = "/pinctrl/suspend/ap-pwroff";
		qos_sdioaudio = "/qos@ffa76000";
		spi2_tx = "/pinctrl/spi2/spi2-tx";
		i2c0_xfer = "/pinctrl/i2c0/i2c0-xfer";
		vcc3v3_sys = "/vcc3v3-sys";
		spi4_clk = "/pinctrl/spi4/spi4-clk";
		vcc3v3_dsi = "/i2c@ff3c0000/pmic@1b/regulators/LDO_REG1";
		edp_in_vopb = "/dp@ff970000/ports/port@0/endpoint@0";
		crypto0 = "/crypto@ff8b0000";
		spi5_rx = "/pinctrl/spi5/spi5-rx";
		pcfg_pull_down = "/pinctrl/pcfg-pull-down";
		pcfg_input_enable = "/pinctrl/pcfg-input-enable";
		pcie_clkreqn_cpm = "/pinctrl/pcie/pci-clkreqn-cpm";
		uart3 = "/serial@ff1b0000";
		pcfg_pull_up = "/pinctrl/pcfg-pull-up";
		qos_vop_big_w = "/qos@ffac8080";
		vpu_mmu = "/iommu@ff650800";
		qos_usb_host1 = "/qos@ffa60180";
		uart1_xfer = "/pinctrl/uart1/uart1-xfer";
		spi2_rx = "/pinctrl/spi2/spi2-rx";
		vcca1v8_hdmi = "/i2c@ff3c0000/pmic@1b/regulators/LDO_REG2";
		sdio0_cd = "/pinctrl/sdio0/sdio0-cd";
		mipi1_out = "/dsi@ff968000/ports/port@1";
		cpub_leakage = "/efuse@ff690000/cpu-leakage@17";
		vcc_phy = "/vcc-phy-regulator";
		i2c6_xfer = "/pinctrl/i2c6/i2c6-xfer";
		cluster0_opp = "/opp-table-0";
		ppi_cluster1 = "/interrupt-controller@fee00000/ppi-partitions/interrupt-partition-1";
		i2c7 = "/i2c@ff160000";
		l2_cache_l = "/cpus/l2-cache-cluster0";
		vccio_sd = "/i2c@ff3c0000/pmic@1b/regulators/LDO_REG4";
		vcc_1v8 = "/i2c@ff3c0000/pmic@1b/regulators/DCDC_REG4";
		sdmmc_cmd = "/pinctrl/sdmmc/sdmmc-cmd";
		uart2b_xfer = "/pinctrl/uart2b/uart2b-xfer";
		u2phy0_typec_hs = "/syscon@ff770000/usb2phy@e450/port/endpoint";
		qos_gmac = "/qos@ffa5c000";
		vopb_out_edp = "/vop@ff900000/port/endpoint@0";
		vopb_out_mipi = "/vop@ff900000/port/endpoint@1";
		pwm2 = "/pwm@ff420020";
		CPU_SLEEP = "/cpus/idle-states/cpu-sleep";
		pcfg_pull_none_18ma = "/pinctrl/pcfg-pull-none-18ma";
		usbdrd_dwc3_1 = "/usb@fe900000/usb@fe900000";
		spi3_cs0 = "/pinctrl/spi3/spi3-cs0";
		qos_video_m0 = "/qos@ffab8000";
		pmu = "/power-management@ff310000";
		pwm2_pin_pull_down = "/pinctrl/pwm2/pwm2-pin-pull-down";
		fan = "/gpio-fan";
		cpu_b0 = "/cpus/cpu@100";
		gpio4 = "/pinctrl/gpio@ff790000";
		gpu_thermal = "/thermal-zones/gpu-thermal";
		uart1 = "/serial@ff190000";
		hdmi = "/hdmi@ff940000";
		vopl_out_hdmi = "/vop@ff8f0000/port/endpoint@2";
		i2s1_2ch_bus_bclk_off = "/pinctrl/i2s1/i2s1-2ch-bus-bclk-off";
		mipi_out = "/dsi@ff960000/ports/port@1";
		cdn_dp = "/dp@fec00000";
		qos_video_m1_w = "/qos@ffac0080";
		hdmi_in_vopl = "/hdmi@ff940000/ports/port@0/endpoint@1";
		hdmi_in = "/hdmi@ff940000/ports/port@0";
		i2c5 = "/i2c@ff140000";
		mipi_dsi = "/dsi@ff960000";
		sdio0_pwr = "/pinctrl/sdio0/sdio0-pwr";
		grf = "/syscon@ff770000";
		mipi1_in = "/dsi@ff968000/ports/port@0";
		usbc_dp = "/i2c@ff3d0000/fusb30x@22/connector/ports/port@2/endpoint";
		dp_in = "/dp@fec00000/ports/port";
		usbdrd3_0 = "/usb@fe800000";
		pcfg_pull_none_20ma = "/pinctrl/pcfg-pull-none-20ma";
		pwm0 = "/pwm@ff420000";
		qos_sd = "/qos@ffa74000";
		hdmi_sound = "/hdmi-sound";
		cpu_l3 = "/cpus/cpu@3";
		sdio0_bus1 = "/pinctrl/sdio0/sdio0-bus1";
		uart0_xfer = "/pinctrl/uart0/uart0-xfer";
		sdio0_int = "/pinctrl/sdio0/sdio0-int";
		mipi_in_vopb = "/dsi@ff960000/ports/port@0/endpoint@0";
		spi4 = "/spi@ff1f0000";
		i2c5_xfer = "/pinctrl/i2c5/i2c5-xfer";
		gpio2 = "/pinctrl/gpio@ff780000";
		center_leakage = "/efuse@ff690000/center-leakage@19";
		spi1_clk = "/pinctrl/spi1/spi1-clk";
		rga = "/rga@ff680000";
		uart2a_xfer = "/pinctrl/uart2a/uart2a-xfer";
		pwm0_pin_pull_down = "/pinctrl/pwm0/pwm0-pin-pull-down";
		emmc_phy = "/syscon@ff770000/phy@f780";
	};

	i2c@ff3d0000 {
		pinctrl-names = "default";
		#address-cells = <0x01>;
		pinctrl-0 = <0x7f>;
		clock-names = "i2c", "pclk";
		assigned-clocks = <0x72 0x0a>;
		i2c-scl-rising-time-ns = <0x1db>;
		i2c-scl-falling-time-ns = <0x1a>;
		assigned-clock-rates = <0xbebc200>;
		interrupts = <0x00 0x38 0x04 0x00>;
		clocks = <0x72 0x0a 0x72 0x1c>;
		#size-cells = <0x00>;
		compatible = "rockchip,rk3399-i2c";
		status = "okay";
		reg = <0x00 0xff3d0000 0x00 0x1000>;
		phandle = <0xfc>;

		fusb30x@22 {
			pinctrl-names = "default";
			pinctrl-0 = <0x80>;
			usb-role-switch = <0x30>;
			interrupts = <0x02 0x08>;
			extcon = <0x30>;
			vbus-supply = <0x81>;
			interrupt-parent = <0x79>;
			compatible = "fcs,fusb302";
			status = "okay";
			reg = <0x22>;
			phandle = <0xfd>;

			connector {
				orientation-switch = <0x30>;
				sink-pdos = <0x2e019032>;
				power-role = "dual";
				source-pdos = <0x2e019032>;
				data-role = "dual";
				label = "USB-C";
				try-power-role = "sink";
				compatible = "usb-c-connector";
				op-sink-microwatt = <0xf4240>;
				mode-switch = <0x30>;

				ports {
					#address-cells = <0x01>;
					#size-cells = <0x00>;

					port@0 {
						reg = <0x00>;

						endpoint {
							remote-endpoint = <0x82>;
							phandle = <0x90>;
						};
					};

					port@1 {
						reg = <0x01>;

						endpoint {
							remote-endpoint = <0x83>;
							phandle = <0x93>;
						};
					};

					port@2 {
						reg = <0x02>;

						endpoint {
							remote-endpoint = <0x84>;
							phandle = <0x92>;
						};
					};
				};

				altmodes {

					dp {
						svid = [ff 01];
						vdo = <0x1c46>;
					};
				};
			};
		};

		vdd_gpu@60 {
			regulator-max-microvolt = <0x124f80>;
			pinctrl-names = "default";
			regulator-boot-on;
			pinctrl-0 = <0x85>;
			regulator-initial-state = <0x03>;
			regulator-always-on;
			regulator-min-microvolt = "", "\f5";
			regulator-name = "vdd_gpu";
			regulator-ramp-delay = <0x3e8>;
			fcs,suspend-voltage-selector = <0x01>;
			compatible = "fcs,fan53200";
			status = "okay";
			reg = <0x60>;
			phandle = <0xb5>;
			vsel-gpios = <0x79 0x0e 0x00>;
			vin-supply = <0x7d>;
			regulator-compatible = "fan53555-regulator";

			regulator-state-mem {
				regulator-off-in-suspend;
			};
		};
	};

	qos@ffac0000 {
		compatible = "rockchip,rk3399-qos", "syscon";
		reg = <0x00 0xffac0000 0x00 0x20>;
		phandle = <0x61>;
	};

	debug@fe430000 {
		clock-names = "apb_pclk";
		clocks = <0x08 0x14d>;
		cpu = <0x02>;
		compatible = "arm,coresight-cpu-debug", "arm,primecell";
		reg = <0x00 0xfe430000 0x00 0x1000>;
	};

	qos@ffa60100 {
		compatible = "rockchip,rk3399-qos", "syscon";
		reg = <0x00 0xffa60100 0x00 0x20>;
		phandle = <0xe9>;
	};

	qos@ffab8000 {
		compatible = "rockchip,rk3399-qos", "syscon";
		reg = <0x00 0xffab8000 0x00 0x20>;
		phandle = <0x60>;
	};

	debug@fe710000 {
		clock-names = "apb_pclk";
		clocks = <0x08 0x14c>;
		cpu = <0x07>;
		compatible = "arm,coresight-cpu-debug", "arm,primecell";
		reg = <0x00 0xfe710000 0x00 0x1000>;
	};

	clock-controller@ff760000 {
		#reset-cells = <0x01>;
		clock-names = "xin24m";
		assigned-clocks = <0x08 0x05 0x08 0x04 0x08 0x06 0x08 0xc0 0x08 0x1c0 0x08 0x140 0x08 0xc2 0x08 0x1c1 0x08 0x142 0x08 0xc9 0x08 0x1c2 0x08 0x143 0x08 0xe3 0x08 0xde 0x08 0x106 0x08 0x178 0x08 0xed>;
		assigned-clock-rates = <0x2367b880 0x2faf0800 0x3b9aca00 0x8f0d180 0x47868c0 0x23c3460 0x5f5e100 0x5f5e100 0x2faf080 0x23c34600 0x5f5e100 0x2faf080 0x17d78400 0x17d78400 0xbebc200 0xbebc200 0x17d78400>;
		clocks = <0x8e>;
		#clock-cells = <0x01>;
		compatible = "rockchip,rk3399-cru";
		rockchip,grf = <0x1f>;
		reg = <0x00 0xff760000 0x00 0x1000>;
		phandle = <0x08>;
	};

	vop@ff8f0000 {
		power-domains = <0x1e 0x12>;
		iommus = <0x98>;
		clock-names = "aclk_vop", "dclk_vop", "hclk_vop";
		assigned-clocks = <0x08 0xdb 0x08 0x1db>;
		assigned-clock-rates = <0x17d78400 0x5f5e100>;
		resets = <0x08 0x113 0x08 0x117 0x08 0x119>;
		interrupts = <0x00 0x77 0x04 0x00>;
		clocks = <0x08 0xdb 0x08 0xb5 0x08 0x1db>;
		compatible = "rockchip,rk3399-vop-lit";
		status = "okay";
		reg = <0x00 0xff8f0000 0x00 0x2000 0x00 0xff8f2000 0x00 0x400>;
		phandle = <0x117>;
		reset-names = "axi", "ahb", "dclk";

		port {
			#address-cells = <0x01>;
			#size-cells = <0x00>;
			phandle = <0x11>;

			endpoint@3 {
				remote-endpoint = <0x9c>;
				reg = <0x03>;
				phandle = <0xb0>;
			};

			endpoint@1 {
				remote-endpoint = <0x9a>;
				reg = <0x01>;
				phandle = <0xb3>;
			};

			endpoint@4 {
				remote-endpoint = <0x9d>;
				reg = <0x04>;
				phandle = <0x35>;
			};

			endpoint@2 {
				remote-endpoint = <0x9b>;
				reg = <0x02>;
				phandle = <0xac>;
			};

			endpoint@0 {
				remote-endpoint = <0x99>;
				reg = <0x00>;
				phandle = <0xae>;
			};
		};
	};

	qos@ffac8080 {
		compatible = "rockchip,rk3399-qos", "syscon";
		reg = <0x00 0xffac8080 0x00 0x20>;
		phandle = <0x70>;
	};

	serial@ff370000 {
		reg-io-width = <0x04>;
		pinctrl-names = "default";
		pinctrl-0 = <0x77>;
		clock-names = "baudclk", "apb_pclk";
		interrupts = <0x00 0x66 0x04 0x00>;
		clocks = <0x72 0x06 0x72 0x22>;
		compatible = "rockchip,rk3399-uart", "snps,dw-apb-uart";
		status = "disabled";
		reg = <0x00 0xff370000 0x00 0x100>;
		phandle = <0xef>;
		reg-shift = <0x02>;
	};

	opp-table-3 {
		compatible = "operating-points-v2";
		phandle = <0x15>;

		opp02 {
			opp-microvolt = <0xdbba0 0xdbba0 0xe1d48>;
			opp-hz = <0x00 0x2faf0800>;
		};

		opp00 {
			opp-microvolt = <0xdbba0 0xdbba0 0xe1d48>;
			opp-hz = <0x00 0x17d78400>;
		};

		opp03 {
			opp-microvolt = <0xe1d48 0xe1d48 0xe1d48>;
			opp-hz = <0x00 0x37502800>;
		};

		opp01 {
			opp-microvolt = <0xdbba0 0xdbba0 0xe1d48>;
			opp-hz = <0x00 0x27b25a80>;
		};
	};

	spdif@ff870000 {
		power-domains = <0x1e 0x1c>;
		pinctrl-names = "default";
		pinctrl-0 = <0x94>;
		clock-names = "mclk", "hclk";
		interrupts = <0x00 0x42 0x04 0x00>;
		clocks = <0x08 0x55 0x08 0x1d7>;
		dma-names = "tx";
		#sound-dai-cells = <0x00>;
		compatible = "rockchip,rk3399-spdif";
		status = "disabled";
		reg = <0x00 0xff870000 0x00 0x1000>;
		phandle = <0x114>;
		dmas = <0x51 0x07>;
	};

	i2c@ff110000 {
		pinctrl-names = "default";
		#address-cells = <0x01>;
		pinctrl-0 = <0x36>;
		clock-names = "i2c", "pclk";
		assigned-clocks = <0x08 0x41>;
		assigned-clock-rates = <0xbebc200>;
		interrupts = <0x00 0x3b 0x04 0x00>;
		clocks = <0x08 0x41 0x08 0x155>;
		#size-cells = <0x00>;
		compatible = "rockchip,rk3399-i2c";
		status = "disabled";
		reg = <0x00 0xff110000 0x00 0x1000>;
		phandle = <0xd5>;
	};

	memory {
		device_type = "memory";
		reg = <0x00 0x200000 0x00 0xf7e00000>;
	};

	mmc@fe310000 {
		power-domains = <0x1e 0x1c>;
		fifo-depth = <0x100>;
		clock-names = "biu", "ciu", "ciu-drive", "ciu-sample";
		resets = <0x08 0x79>;
		interrupts = <0x00 0x40 0x04 0x00>;
		clocks = <0x08 0x1ee 0x08 0x4d 0x08 0x9c 0x08 0x9d>;
		compatible = "rockchip,rk3399-dw-mshc", "rockchip,rk3288-dw-mshc";
		status = "disabled";
		reg = <0x00 0xfe310000 0x00 0x4000>;
		phandle = <0xc6>;
		max-frequency = <0x8f0d180>;
		reset-names = "reset";
	};

	pwm@ff420030 {
		pinctrl-names = "default";
		pinctrl-0 = <0x8a>;
		clocks = <0x72 0x1e>;
		#pwm-cells = <0x03>;
		compatible = "rockchip,rk3399-pwm", "rockchip,rk3288-pwm";
		status = "disabled";
		reg = <0x00 0xff420030 0x00 0x10>;
		phandle = <0x102>;
	};

	qos@ffa90000 {
		compatible = "rockchip,rk3399-qos", "syscon";
		reg = <0x00 0xffa90000 0x00 0x20>;
		phandle = <0x6a>;
	};

	qos@ffa60080 {
		compatible = "rockchip,rk3399-qos", "syscon";
		reg = <0x00 0xffa60080 0x00 0x20>;
		phandle = <0xe8>;
	};
};
